VERSION "2024.1"

NS_ :

BS_ :

BU_: SB_FRONT STEERING TPMS DATALOGGER BMS_LV DIAG_TOOL SB_REAR SCANNER EXTRA_NODE TLB_BAT BRUSA DASH DSPACE IMU

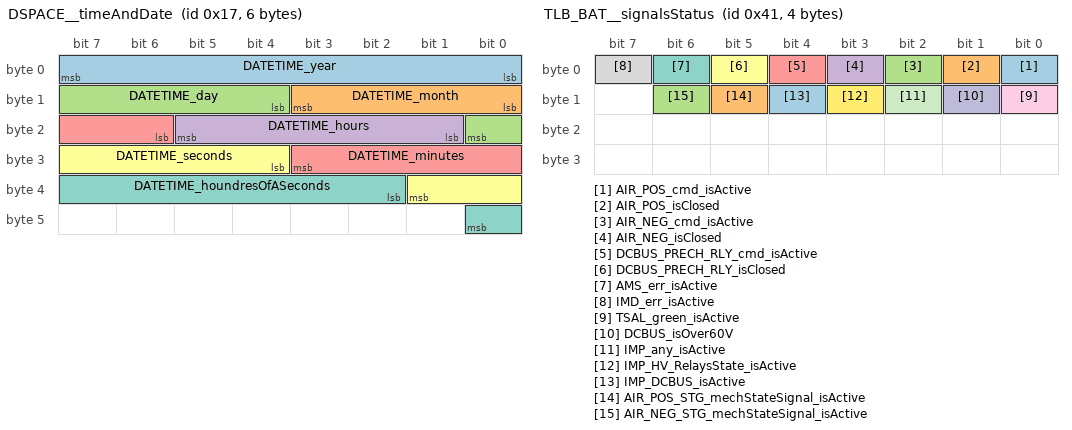
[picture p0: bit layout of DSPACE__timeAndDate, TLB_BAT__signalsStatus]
BO_ 23 DSPACE__timeAndDate: 6 DSPACE
  SG_ DATETIME_year : 0|8@1+ (1,0) [0|255] "" DASH,SB_FRONT,SB_REAR,SCANNER,TLB_BAT,BMS_LV
  SG_ DATETIME_month : 8|4@1+ (1,0) [0|11] "" DASH,SB_FRONT,SB_REAR,SCANNER,TLB_BAT,BMS_LV
  SG_ DATETIME_day : 12|5@1+ (1,0) [1|31] "" DASH,SB_FRONT,SB_REAR,SCANNER,TLB_BAT,BMS_LV
  SG_ DATETIME_hours : 17|5@1+ (1,0) [0|23] "h" DASH,SB_FRONT,SB_REAR,SCANNER,TLB_BAT,BMS_LV
  SG_ DATETIME_minutes : 22|6@1+ (1,0) [0|59] "min" DASH,SB_FRONT,SB_REAR,SCANNER,TLB_BAT,BMS_LV
  SG_ DATETIME_seconds : 28|6@1+ (1,0) [0|59] "sec" DASH,SB_FRONT,SB_REAR,SCANNER,TLB_BAT,BMS_LV
  SG_ DATETIME_houndresOfASeconds : 34|7@1+ (1,0) [0|99] "sec" DASH,SB_FRONT,SB_REAR,SCANNER,TLB_BAT,BMS_LV

BO_ 65 TLB_BAT__signalsStatus: 4 TLB_BAT
  SG_ AIR_POS_cmd_isActive : 0|1@1+ (1,0) [0|1] "" DSPACE,SCANNER
  SG_ AIR_POS_isClosed : 1|1@1+ (1,0) [0|1] "" DSPACE,SCANNER
  SG_ AIR_NEG_cmd_isActive : 2|1@1+ (1,0) [0|1] "" DSPACE,SCANNER
  SG_ AIR_NEG_isClosed : 3|1@1+ (1,0) [0|1] "" DSPACE,SCANNER
  SG_ DCBUS_PRECH_RLY_cmd_isActive : 4|1@1+ (1,0) [0|1] "" DSPACE,SCANNER
  SG_ DCBUS_PRECH_RLY_isClosed : 5|1@1+ (1,0) [0|1] "" DSPACE,SCANNER
  SG_ AMS_err_isActive : 6|1@1+ (1,0) [0|1] "" DSPACE,SCANNER
  SG_ IMD_err_isActive : 7|1@1+ (1,0) [0|1] "" DSPACE,SCANNER
  SG_ TSAL_green_isActive : 8|1@1+ (1,0) [0|1] "" DSPACE,SCANNER
  SG_ DCBUS_isOver60V : 9|1@1+ (1,0) [0|1] "" DSPACE,SCANNER
  SG_ IMP_any_isActive : 10|1@1+ (1,0) [0|1] "" DSPACE,SCANNER
  SG_ IMP_HV_RelaysState_isActive : 11|1@1+ (1,0) [0|1] "" DSPACE,SCANNER
  SG_ IMP_DCBUS_isActive : 12|1@1+ (1,0) [0|1] "" DSPACE,SCANNER
  SG_ AIR_POS_STG_mechStateSignal_isActive : 13|1@1+ (1,0) [0|1] "" DSPACE,SCANNER
  SG_ AIR_NEG_STG_mechStateSignal_isActive : 14|1@1+ (1,0) [0|1] "" DSPACE,SCANNER

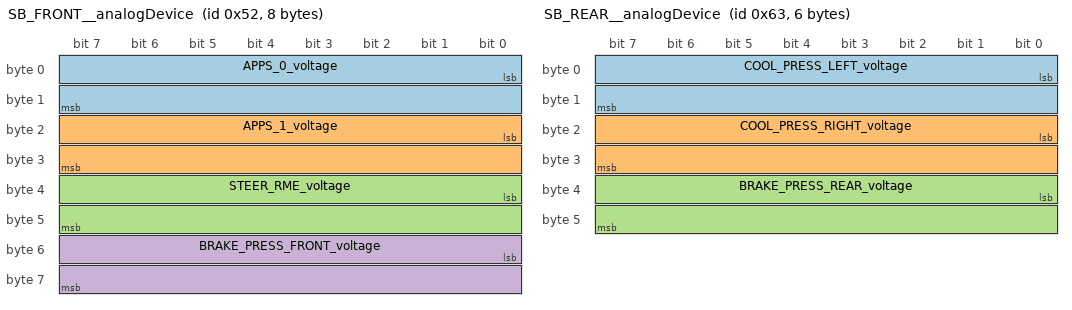
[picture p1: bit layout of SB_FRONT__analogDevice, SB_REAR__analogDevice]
BO_ 82 SB_FRONT__analogDevice: 8 SB_FRONT
  SG_ APPS_0_voltage : 0|16@1+ (1,0) [0|65535] "mV" DSPACE,SCANNER
  SG_ APPS_1_voltage : 16|16@1+ (1,0) [0|65535] "mV" DSPACE,SCANNER
  SG_ STEER_RME_voltage : 32|16@1+ (1,0) [0|65535] "mV" DSPACE,SCANNER
  SG_ BRAKE_PRESS_FRONT_voltage : 48|16@1+ (1,0) [0|8192] "mV" DSPACE,SCANNER

BO_ 83 SB_FRONT_emergency_brake_sensors: 4 SB_FRONT
  SG_ EMERGENCY_BRAKE_PRESS_PNEU_voltage : 0|16@1+ (1,0) [0|65535] "mV" DSPACE,SCANNER
  SG_ REDUNDANCY_BRAKE_PRESS_PNEU_voltage : 16|16@1+ (1,0) [0|65535] "mV" DSPACE,SCANNER

BO_ 99 SB_REAR__analogDevice: 6 SB_REAR
  SG_ COOL_PRESS_LEFT_voltage : 0|16@1+ (1,0) [0|65535] "mV" DSPACE,SCANNER
  SG_ COOL_PRESS_RIGHT_voltage : 16|16@1+ (1,0) [0|65535] "mV" DSPACE,SCANNER
  SG_ BRAKE_PRESS_REAR_voltage : 32|16@1+ (1,0) [0|65535] "mV" DSPACE,SCANNER

BO_ 115 SB_REAR__criticalPeripherals: 1 SB_REAR
  SG_ DISCHARGE_isActive : 0|1@1+ (1,0) [0|1] "" DSPACE,SCANNER
  SG_ BSPD_hasError : 1|1@1+ (1,0) [0|1] "" DSPACE,SCANNER

BO_ 131 SB_REAR__coldplateCircuitPressure: 2 SB_REAR
  SG_ COLDPLATE_CIRCUIT_PRESS_voltage : 0|16@1+ (1,0) [0|65535] "mV" DSPACE,SCANNER

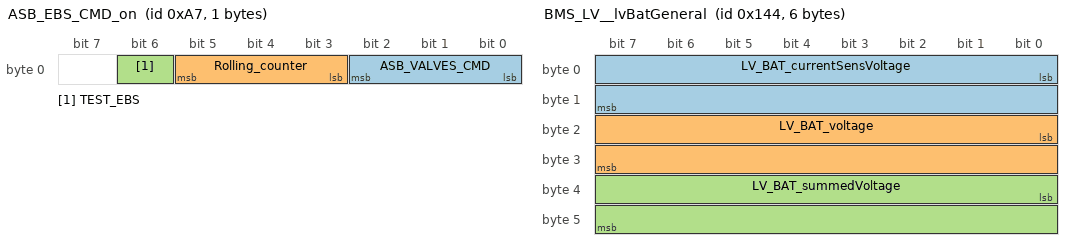
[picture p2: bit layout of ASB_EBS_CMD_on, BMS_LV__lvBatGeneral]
BO_ 167 ASB_EBS_CMD_on: 1 DSPACE
  SG_ ASB_VALVES_CMD : 0|3@1+ (1,0) [1|4] "" DASH
  SG_ Rolling_counter : 3|3@1+ (1,0) [0|7] "" DASH
  SG_ TEST_EBS : 6|1@1+ (1,0) [0|1] "" DASH

BO_ 324 BMS_LV__lvBatGeneral: 6 BMS_LV
  SG_ LV_BAT_currentSensVoltage : 0|16@1+ (0.076,0) [0|4980.66] "mV" DSPACE,SCANNER
  SG_ LV_BAT_voltage : 16|16@1+ (0.267,14000) [0|17497.845] "mV" DSPACE,SCANNER
  SG_ LV_BAT_summedVoltage : 32|16@1+ (0.267,14000) [0|17497.845] "mV" DSPACE,SCANNER

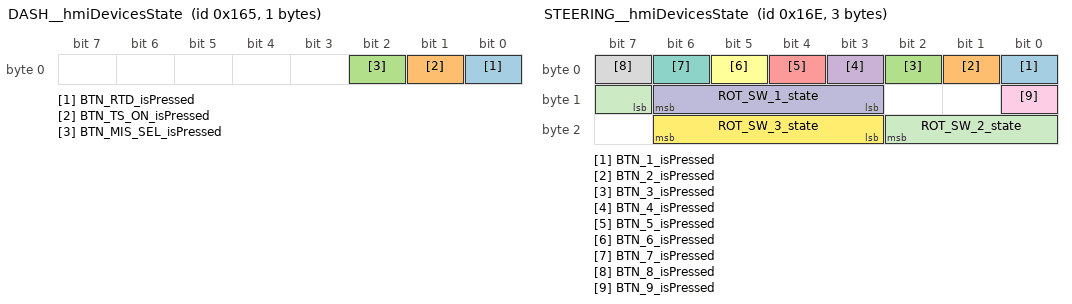
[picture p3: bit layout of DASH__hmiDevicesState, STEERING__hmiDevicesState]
BO_ 357 DASH__hmiDevicesState: 1 DASH
  SG_ BTN_RTD_isPressed : 0|1@1+ (1,0) [0|255] "" DSPACE,SCANNER
  SG_ BTN_TS_ON_isPressed : 1|1@1+ (1,0) [0|255] "" DSPACE,SCANNER
  SG_ BTN_MIS_SEL_isPressed : 2|1@1+ (1,0) [0|255] "" DSPACE,SCANNER

BO_ 366 STEERING__hmiDevicesState: 3 STEERING
  SG_ BTN_1_isPressed : 0|1@1+ (1,0) [0|1] "" DSPACE,SCANNER,DASH
  SG_ BTN_2_isPressed : 1|1@1+ (1,0) [0|1] "" DSPACE,SCANNER,DASH
  SG_ BTN_3_isPressed : 2|1@1+ (1,0) [0|1] "" DSPACE,SCANNER,DASH
  SG_ BTN_4_isPressed : 3|1@1+ (1,0) [0|1] "" DSPACE,SCANNER,DASH
  SG_ BTN_5_isPressed : 4|1@1+ (1,0) [0|1] "" DSPACE,SCANNER,DASH
  SG_ BTN_6_isPressed : 5|1@1+ (1,0) [0|1] "" DSPACE,SCANNER,DASH
  SG_ BTN_7_isPressed : 6|1@1+ (1,0) [0|1] "" DSPACE,SCANNER,DASH
  SG_ BTN_8_isPressed : 7|1@1+ (1,0) [0|1] "" DSPACE,SCANNER,DASH
  SG_ BTN_9_isPressed : 8|1@1+ (1,0) [0|1] "" DSPACE,SCANNER,DASH
  SG_ ROT_SW_1_state : 11|4@1+ (1,0) [0|9] "" DSPACE,SCANNER,DASH
  SG_ ROT_SW_2_state : 15|4@1+ (1,0) [0|9] "" DSPACE,SCANNER,DASH
  SG_ ROT_SW_3_state : 19|4@1+ (1,0) [0|9] "" DSPACE,SCANNER,DASH

BO_ 373 Rolling_not_commuted: 1 DASH
  SG_ No_counter_change_notify : 0|1@1+ (1,0) [0|1] "" DSPACE

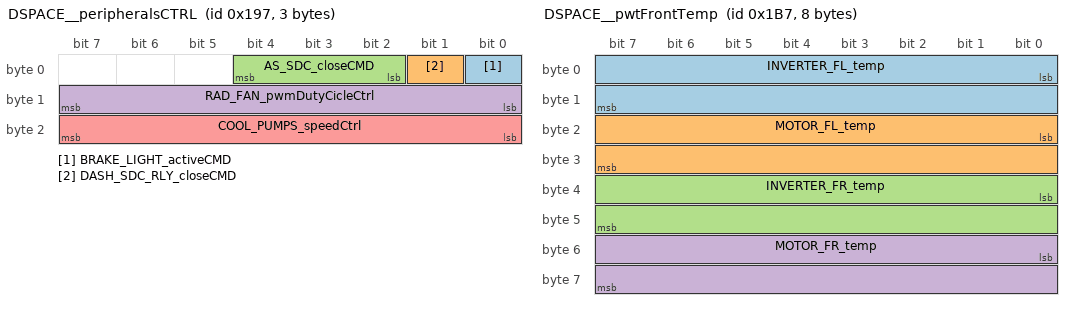
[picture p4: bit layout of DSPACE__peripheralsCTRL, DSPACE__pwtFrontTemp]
BO_ 407 DSPACE__peripheralsCTRL: 3 DSPACE
  SG_ BRAKE_LIGHT_activeCMD : 0|1@1+ (1,0) [0|1] "" DASH,SB_REAR,SCANNER
  SG_ DASH_SDC_RLY_closeCMD : 1|1@1+ (1,0) [0|1] "" DASH,SCANNER
  SG_ AS_SDC_closeCMD : 2|3@1+ (1,0) [0|3] "" DASH,SCANNER
  SG_ RAD_FAN_pwmDutyCicleCtrl : 8|8@1+ (1,0) [0|100] "%" DASH,SB_REAR,SCANNER
  SG_ COOL_PUMPS_speedCtrl : 16|8@1+ (1,0) [0|100] "%" DASH,SB_REAR,SCANNER

BO_ 439 DSPACE__pwtFrontTemp: 8 DSPACE
  SG_ INVERTER_FL_temp : 0|16@1+ (1,0) [-3276|3276] "degC" DASH,SCANNER
  SG_ MOTOR_FL_temp : 16|16@1+ (1,0) [-3276|3276] "degC" DASH,SCANNER
  SG_ INVERTER_FR_temp : 32|16@1+ (1,0) [-3276|3276] "degC" DASH,SCANNER
  SG_ MOTOR_FR_temp : 48|16@1+ (1,0) [-3276|3276] "degC" DASH,SCANNER

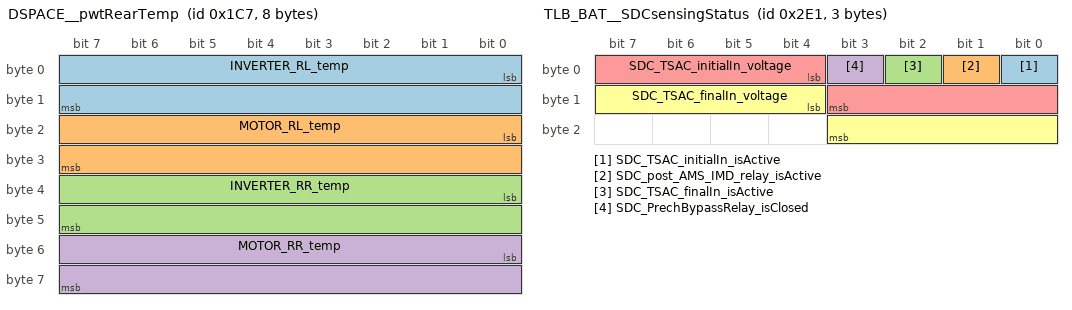
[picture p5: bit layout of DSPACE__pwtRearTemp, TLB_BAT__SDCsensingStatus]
BO_ 455 DSPACE__pwtRearTemp: 8 DSPACE
  SG_ INVERTER_RL_temp : 0|16@1+ (1,0) [-3276|3276] "degC" DASH,SCANNER
  SG_ MOTOR_RL_temp : 16|16@1+ (1,0) [-3276|3276] "degC" DASH,SCANNER
  SG_ INVERTER_RR_temp : 32|16@1+ (1,0) [-3276|3276] "degC" DASH,SCANNER
  SG_ MOTOR_RR_temp : 48|16@1+ (1,0) [-3276|3276] "degC" DASH,SCANNER

BO_ 646 DIAG_TOOL__xcpTxBMS_LV: 8 DIAG_TOOL
  SG_ xcp_payload : 0|64@1+ (1,0) [0|0] "" BMS_LV

BO_ 662 DIAG_TOOL__xcpTxDASH: 8 DIAG_TOOL
  SG_ xcp_payload : 0|64@1+ (1,0) [0|0] "" DASH

BO_ 678 DIAG_TOOL__xcpTxSB_REAR: 8 DIAG_TOOL
  SG_ xcp_payload : 0|64@1+ (1,0) [0|0] "" SB_REAR

BO_ 694 DIAG_TOOL__xcpTxSB_FRONT: 8 DIAG_TOOL
  SG_ xcp_payload : 0|64@1+ (1,0) [0|0] "" SB_FRONT

BO_ 710 DIAG_TOOL__xcpTxSCANNER: 8 DIAG_TOOL
  SG_ xcp_payload : 0|64@1+ (1,0) [0|0] "" SCANNER

BO_ 726 DIAG_TOOL__xcpTxTLB_BAT: 8 DIAG_TOOL
  SG_ xcp_payload : 0|64@1+ (1,0) [0|0] "" TLB_BAT

BO_ 737 TLB_BAT__SDCsensingStatus: 3 TLB_BAT
  SG_ SDC_TSAC_initialIn_isActive : 0|1@1+ (1,0) [0|1] "" DSPACE,SCANNER
  SG_ SDC_post_AMS_IMD_relay_isActive : 1|1@1+ (1,0) [0|1] "" DSPACE,SCANNER
  SG_ SDC_TSAC_finalIn_isActive : 2|1@1+ (1,0) [0|1] "" DSPACE,SCANNER
  SG_ SDC_PrechBypassRelay_isClosed : 3|1@1+ (1,0) [0|1] "" DSPACE,SCANNER
  SG_ SDC_TSAC_initialIn_voltage : 4|8@1+ (0.177,0) [0|255] "V" DSPACE,SCANNER
  SG_ SDC_TSAC_finalIn_voltage : 12|8@1+ (0.177,0) [0|255] "V" DSPACE,SCANNER

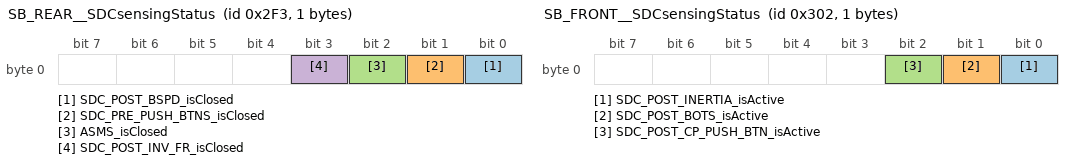
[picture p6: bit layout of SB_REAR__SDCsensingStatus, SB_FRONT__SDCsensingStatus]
BO_ 755 SB_REAR__SDCsensingStatus: 1 SB_REAR
  SG_ SDC_POST_BSPD_isClosed : 0|1@1+ (1,0) [0|1] "" DSPACE,SCANNER
  SG_ SDC_PRE_PUSH_BTNS_isClosed : 1|1@1+ (1,0) [0|1] "" DSPACE,SCANNER
  SG_ ASMS_isClosed : 2|1@1+ (1,0) [0|1] "" DSPACE,SCANNER
  SG_ SDC_POST_INV_FR_isClosed : 3|1@1+ (1,0) [0|1] "" DSPACE,SCANNER

BO_ 770 SB_FRONT__SDCsensingStatus: 1 SB_FRONT
  SG_ SDC_POST_INERTIA_isActive : 0|1@1+ (1,0) [0|1] "" DSPACE,SCANNER
  SG_ SDC_POST_BOTS_isActive : 1|1@1+ (1,0) [0|1] "" DSPACE,SCANNER
  SG_ SDC_POST_CP_PUSH_BTN_isActive : 2|1@1+ (1,0) [0|1] "" DSPACE,SCANNER

BO_ 802 SB_FRONT__potentiometer: 4 SB_FRONT
  SG_ LPPS_DAMPER_FL_voltage : 0|16@1+ (1,0) [0|65535] "mV" DSPACE,SCANNER
  SG_ LPPS_DAMPER_FR_voltage : 16|16@1+ (1,0) [0|65535] "mV" DSPACE,SCANNER

BO_ 819 SB_REAR__potentiometer: 4 SB_REAR
  SG_ LPPS_DAMPER_RL_voltage : 0|16@1+ (1,0) [0|65535] "mV" DSPACE,SCANNER
  SG_ LPPS_DAMPER_RR_voltage : 16|16@1+ (1,0) [0|65535] "mV" DSPACE,SCANNER

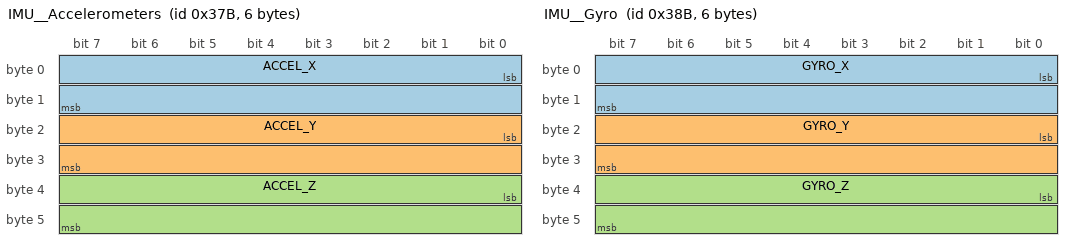
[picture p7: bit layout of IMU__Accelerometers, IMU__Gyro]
BO_ 891 IMU__Accelerometers: 6 IMU
  SG_ ACCEL_X : 0|16@1- (0.01,0) [-327.68|327.67] "m.s-2" Vector__XXX
  SG_ ACCEL_Y : 16|16@1- (0.01,0) [-327.68|327.67] "m.s-2" Vector__XXX
  SG_ ACCEL_Z : 32|16@1- (0.01,0) [-327.68|327.67] "m.s-2" Vector__XXX

BO_ 907 IMU__Gyro: 6 IMU
  SG_ GYRO_X : 0|16@1- (0.001,0) [-32.768|32.767] "rad.s-1" Vector__XXX
  SG_ GYRO_Y : 16|16@1- (0.001,0) [-32.768|32.767] "rad.s-1" Vector__XXX
  SG_ GYRO_Z : 32|16@1- (0.001,0) [-32.768|32.767] "rad.s-1" Vector__XXX

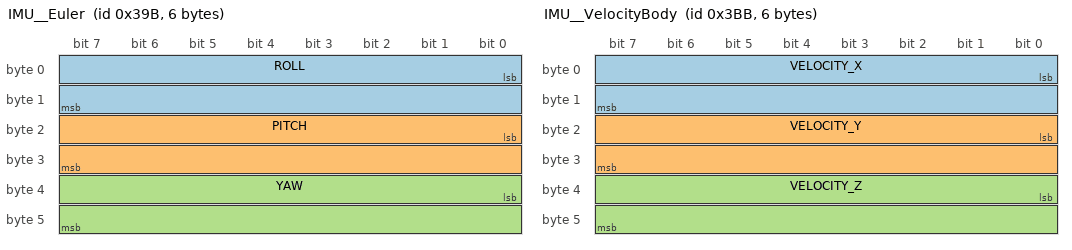
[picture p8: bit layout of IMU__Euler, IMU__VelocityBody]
BO_ 923 IMU__Euler: 6 IMU
  SG_ ROLL : 0|16@1- (0.0001,0) [-3.2768|3.2767] "rad" Vector__XXX
  SG_ PITCH : 16|16@1- (0.0001,0) [-3.2768|3.2767] "rad" Vector__XXX
  SG_ YAW : 32|16@1- (0.0001,0) [-3.2768|3.2767] "rad" Vector__XXX

BO_ 939 IMU__GPS1_Position: 8 IMU
  SG_ LATITUDE : 0|32@1- (0.0000001,0) [-214.7483648|214.7483647] "�" Vector__XXX
  SG_ LONGITUDE : 32|32@1- (0.0000001,0) [-214.7483648|214.7483647] "�" Vector__XXX

BO_ 955 IMU__VelocityBody: 6 IMU
  SG_ VELOCITY_X : 0|16@1- (0.01,0) [-327.68|327.67] "m.s-1" Vector__XXX
  SG_ VELOCITY_Y : 16|16@1- (0.01,0) [-327.68|327.67] "m.s-1" Vector__XXX
  SG_ VELOCITY_Z : 32|16@1- (0.01,0) [-327.68|327.67] "m.s-1" Vector__XXX

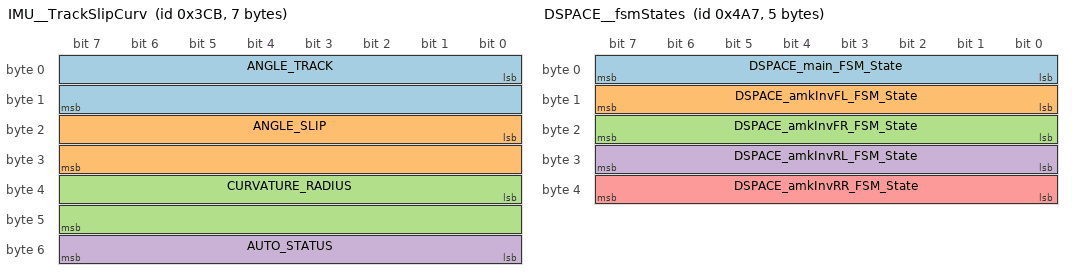
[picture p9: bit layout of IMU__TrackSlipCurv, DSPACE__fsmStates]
BO_ 971 IMU__TrackSlipCurv: 7 IMU
  SG_ ANGLE_TRACK : 0|16@1- (0.0001,0) [-3.2768|3.2767] "rad" Vector__XXX
  SG_ ANGLE_SLIP : 16|16@1- (0.0001,0) [-3.2768|3.2767] "rad" Vector__XXX
  SG_ CURVATURE_RADIUS : 32|16@1+ (0.01,0) [0|655.35] "m" Vector__XXX
  SG_ AUTO_STATUS : 48|8@1+ (1,0) [0|255] "" Vector__XXX

BO_ 1121 TLB_BAT__xcpTx: 8 TLB_BAT
  SG_ xcp_payload : 0|64@1+ (1,0) [0|0] "" DIAG_TOOL

BO_ 1122 SB_FRONT__xcpTx: 8 SB_FRONT
  SG_ xcp_payload : 0|64@1+ (1,0) [0|0] "" DIAG_TOOL

BO_ 1123 SB_REAR__xcpTx: 8 SB_REAR
  SG_ xcp_payload : 0|64@1+ (1,0) [0|0] "" DIAG_TOOL

BO_ 1124 BMS_LV__xcpTx: 8 BMS_LV
  SG_ xcp_payload : 0|64@1+ (1,0) [0|0] "" DIAG_TOOL

BO_ 1125 DASH__xcpTx: 8 DASH
  SG_ xcp_payload : 0|64@1+ (1,0) [0|0] "" DIAG_TOOL

BO_ 1127 DSPACE__xcpTx: 8 DSPACE
  SG_ xcp_payload : 0|64@1+ (1,0) [0|0] "" DIAG_TOOL

BO_ 1129 SCANNER__xcpTx: 8 SCANNER
  SG_ xcp_payload : 0|64@1+ (1,0) [0|0] "" DIAG_TOOL

BO_ 1143 DSPACE__autonomousMission: 1 DSPACE
  SG_ autonomousMission_state : 0|4@1+ (1,0) [0|7] "" DASH,SCANNER

BO_ 1175 DSPACE__signals: 2 DSPACE
  SG_ HVBAT_soc : 0|8@1+ (1,0) [100|0] "%" DASH,SCANNER
  SG_ ASSI_command : 8|3@1+ (1,0) [0|5] "" DASH,SCANNER

BO_ 1191 DSPACE__fsmStates: 5 DSPACE
  SG_ DSPACE_main_FSM_State : 0|8@1- (1,0) [-1|5] "" DASH,SCANNER
  SG_ DSPACE_amkInvFL_FSM_State : 8|8@1- (1,0) [0|6] "" DASH,SCANNER
  SG_ DSPACE_amkInvFR_FSM_State : 16|8@1- (1,0) [0|6] "" DASH,SCANNER
  SG_ DSPACE_amkInvRL_FSM_State : 24|8@1- (1,0) [0|6] "" DASH,SCANNER
  SG_ DSPACE_amkInvRR_FSM_State : 32|8@1- (1,0) [0|6] "" DASH,SCANNER

BO_ 1204 BMS_LV__cellsStatus: 5 BMS_LV
  SG_ LV_CELL_0_isOV : 0|1@1+ (1,0) [0|1] "" DSPACE,SCANNER
  SG_ LV_CELL_0_isUV : 1|1@1+ (1,0) [0|1] "" DSPACE,SCANNER
  SG_ LV_CELL_1_isOV : 2|1@1+ (1,0) [0|1] "" DSPACE,SCANNER
  SG_ LV_CELL_1_isUV : 3|1@1+ (1,0) [0|1] "" DSPACE,SCANNER
  SG_ LV_CELL_2_isOV : 4|1@1+ (1,0) [0|1] "" DSPACE,SCANNER
  SG_ LV_CELL_2_isUV : 5|1@1+ (1,0) [0|1] "" DSPACE,SCANNER
  SG_ LV_CELL_3_isOV : 6|1@1+ (1,0) [0|1] "" DSPACE,SCANNER
  SG_ LV_CELL_3_isUV : 7|1@1+ (1,0) [0|1] "" DSPACE,SCANNER
  SG_ LV_CELL_4_isOV : 8|1@1+ (1,0) [0|1] "" DSPACE,SCANNER
  SG_ LV_CELL_4_isUV : 9|1@1+ (1,0) [0|1] "" DSPACE,SCANNER
  SG_ LV_CELL_5_isOV : 10|1@1+ (1,0) [0|1] "" DSPACE,SCANNER
  SG_ LV_CELL_5_isUV : 11|1@1+ (1,0) [0|1] "" DSPACE,SCANNER
  SG_ LV_CELL_6_isOV : 12|1@1+ (1,0) [0|1] "" DSPACE,SCANNER
  SG_ LV_CELL_6_isUV : 13|1@1+ (1,0) [0|1] "" DSPACE,SCANNER
  SG_ LV_CELL_NTC_00_isOT : 14|1@1+ (1,0) [0|1] "" DSPACE,SCANNER
  SG_ LV_CELL_NTC_01_isOT : 15|1@1+ (1,0) [0|1] "" DSPACE,SCANNER
  SG_ LV_CELL_NTC_02_isOT : 16|1@1+ (1,0) [0|1] "" DSPACE,SCANNER
  SG_ LV_CELL_NTC_03_isOT : 17|1@1+ (1,0) [0|1] "" DSPACE,SCANNER
  SG_ LV_CELL_NTC_04_isOT : 18|1@1+ (1,0) [0|1] "" DSPACE,SCANNER
  SG_ LV_CELL_NTC_05_isOT : 19|1@1+ (1,0) [0|1] "" DSPACE,SCANNER
  SG_ LV_CELL_NTC_06_isOT : 20|1@1+ (1,0) [0|1] "" DSPACE,SCANNER
  SG_ LV_CELL_NTC_07_isOT : 21|1@1+ (1,0) [0|1] "" DSPACE,SCANNER
  SG_ LV_CELL_NTC_08_isOT : 22|1@1+ (1,0) [0|1] "" DSPACE,SCANNER
  SG_ LV_CELL_NTC_09_isOT : 23|1@1+ (1,0) [0|1] "" DSPACE,SCANNER
  SG_ LV_CELL_NTC_10_isOT : 24|1@1+ (1,0) [0|1] "" DSPACE,SCANNER
  SG_ LV_CELL_NTC_11_isOT : 25|1@1+ (1,0) [0|1] "" DSPACE,SCANNER
  SG_ LV_CELL_NTC_12_isOT : 26|1@1+ (1,0) [0|1] "" DSPACE,SCANNER

BO_ 1220 BMS_LV__status: 1 BMS_LV
  SG_ LV_RELAY_isClosed : 0|1@1+ (1,0) [0|1] "" DSPACE,SCANNER
  SG_ LV_RELAY_isRelayOverrideOn : 1|1@1+ (1,0) [0|1] "" DSPACE,SCANNER

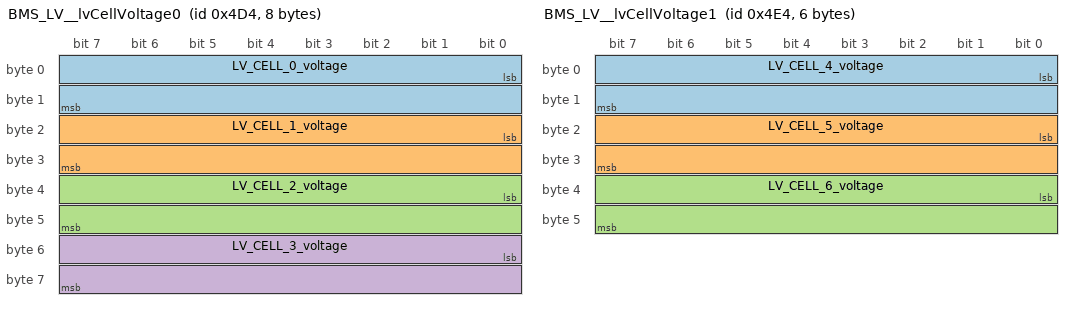
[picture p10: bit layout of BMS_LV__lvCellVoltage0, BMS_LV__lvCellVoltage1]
BO_ 1236 BMS_LV__lvCellVoltage0: 8 BMS_LV
  SG_ LV_CELL_0_voltage : 0|16@1+ (0.038,2000) [0|2490.33] "mV" DSPACE,SCANNER
  SG_ LV_CELL_1_voltage : 16|16@1+ (0.038,2000) [0|2490.33] "mV" DSPACE,SCANNER
  SG_ LV_CELL_2_voltage : 32|16@1+ (0.038,2000) [0|2490.33] "mV" DSPACE,SCANNER
  SG_ LV_CELL_3_voltage : 48|16@1+ (0.038,2000) [0|2490.33] "mV" DSPACE,SCANNER

BO_ 1252 BMS_LV__lvCellVoltage1: 6 BMS_LV
  SG_ LV_CELL_4_voltage : 0|16@1+ (0.038,2000) [0|2490.33] "mV" DSPACE,SCANNER
  SG_ LV_CELL_5_voltage : 16|16@1+ (0.038,2000) [0|2490.33] "mV" DSPACE,SCANNER
  SG_ LV_CELL_6_voltage : 32|16@1+ (0.038,2000) [0|2490.33] "mV" DSPACE,SCANNER

BO_ 1269 DASH__peripheralsStatus: 1 DASH
  SG_ TSAC_FAN_pwmDutyCycleStatus : 0|4@1+ (1,0) [0|10] "%" DSPACE,SCANNER

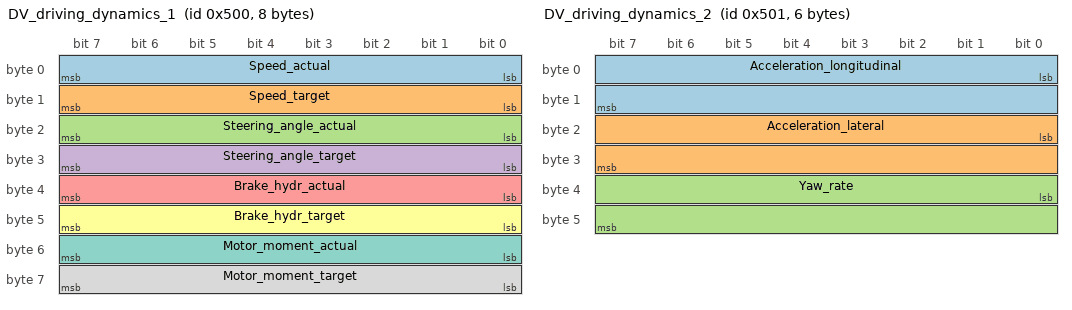
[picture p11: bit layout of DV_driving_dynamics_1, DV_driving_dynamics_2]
BO_ 1280 DV_driving_dynamics_1: 8 DSPACE
  SG_ Speed_actual : 0|8@1+ (1,0) [0|255] "" DATALOGGER
  SG_ Speed_target : 8|8@1+ (1,0) [0|255] "" DATALOGGER
  SG_ Steering_angle_actual : 16|8@1- (0.5,0) [-64|63.5] "" DATALOGGER
  SG_ Steering_angle_target : 24|8@1- (0.5,0) [-64|63.5] "" DATALOGGER
  SG_ Brake_hydr_actual : 32|8@1+ (1,0) [0|255] "" DATALOGGER
  SG_ Brake_hydr_target : 40|8@1+ (1,0) [0|255] "" DATALOGGER
  SG_ Motor_moment_actual : 48|8@1- (1,0) [-128|127] "" DATALOGGER
  SG_ Motor_moment_target : 56|8@1- (1,0) [-128|127] "" DATALOGGER

BO_ 1281 DV_driving_dynamics_2: 6 DSPACE
  SG_ Acceleration_longitudinal : 0|16@1- (0.001953125,0) [-64|63.998046875] "" DATALOGGER
  SG_ Acceleration_lateral : 16|16@1- (0.001953125,0) [-64|63.998046875] "" DATALOGGER
  SG_ Yaw_rate : 32|16@1- (0.0078125,0) [-256|255.9921875] "" DATALOGGER

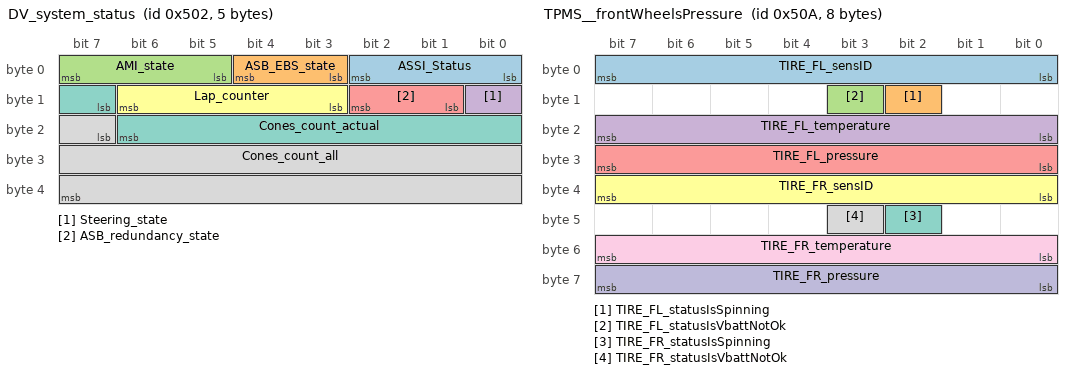
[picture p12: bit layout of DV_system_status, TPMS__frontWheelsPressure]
BO_ 1282 DV_system_status: 5 DSPACE
  SG_ ASSI_Status : 0|3@1+ (1,0) [1|5] "" DATALOGGER,DASH
  SG_ ASB_EBS_state : 3|2@1+ (1,0) [1|3] "" DATALOGGER,DASH
  SG_ AMI_state : 5|3@1+ (1,0) [1|6] "" DATALOGGER,DASH
  SG_ Steering_state : 8|1@1+ (1,0) [0|1] "" DATALOGGER
  SG_ ASB_redundancy_state : 9|2@1+ (1,0) [1|3] "" DATALOGGER
  SG_ Lap_counter : 11|4@1+ (1,0) [0|15] "" DATALOGGER
  SG_ Cones_count_actual : 15|8@1+ (1,0) [0|255] "" DATALOGGER
  SG_ Cones_count_all : 23|17@1+ (1,0) [0|131071] "" DATALOGGER

BO_ 1290 TPMS__frontWheelsPressure: 8 TPMS
  SG_ TIRE_FL_sensID : 0|8@1+ (1,0) [1|255] "" DSPACE,SCANNER
  SG_ TIRE_FL_statusIsSpinning : 10|1@1+ (1,0) [0|1] "" DSPACE,SCANNER
  SG_ TIRE_FL_statusIsVbattNotOk : 11|1@1+ (1,0) [0|1] "" DSPACE,SCANNER
  SG_ TIRE_FL_temperature : 16|8@1+ (1,-50) [10|170] "degC" DSPACE,SCANNER
  SG_ TIRE_FL_pressure : 24|8@1+ (13.7035,-0.7035) [1|254] "mB" DSPACE,SCANNER
  SG_ TIRE_FR_sensID : 32|8@1+ (1,0) [1|255] "" DSPACE,SCANNER
  SG_ TIRE_FR_statusIsSpinning : 42|1@1+ (1,0) [0|1] "" DSPACE,SCANNER
  SG_ TIRE_FR_statusIsVbattNotOk : 43|1@1+ (1,0) [0|1] "" DSPACE,SCANNER
  SG_ TIRE_FR_temperature : 48|8@1+ (1,-50) [10|170] "degC" DSPACE,SCANNER
  SG_ TIRE_FR_pressure : 56|8@1+ (13.7035,-0.7035) [1|254] "mB" DSPACE,SCANNER

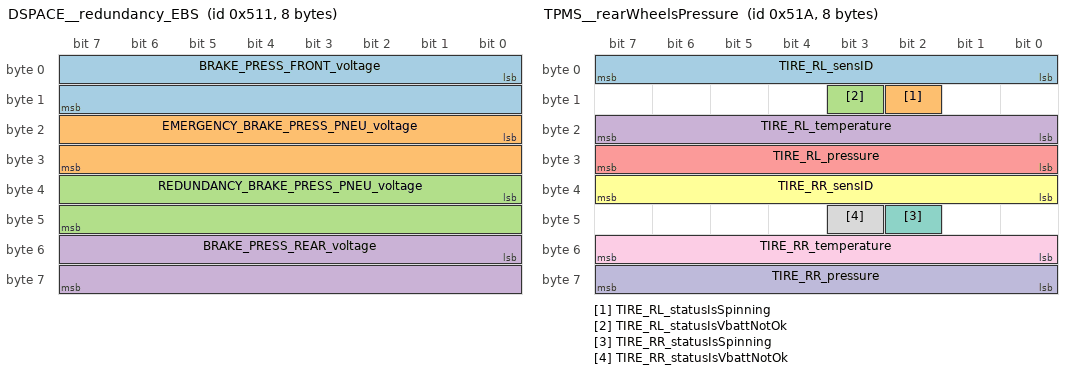
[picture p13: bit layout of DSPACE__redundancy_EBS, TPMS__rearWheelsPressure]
BO_ 1297 DSPACE__redundancy_EBS: 8 DSPACE
  SG_ BRAKE_PRESS_FRONT_voltage : 0|16@1+ (0.025,-12.5) [0|200] "bar" SB_FRONT,DATALOGGER
  SG_ EMERGENCY_BRAKE_PRESS_PNEU_voltage : 16|16@1+ (0.025,-12.5) [0|200] "bar" SB_FRONT,DATALOGGER
  SG_ REDUNDANCY_BRAKE_PRESS_PNEU_voltage : 32|16@1+ (0.025,-12.5) [0|200] "bar" SB_FRONT,DATALOGGER
  SG_ BRAKE_PRESS_REAR_voltage : 48|16@1+ (0.025,-12.5) [0|200] "bar" SB_REAR,DATALOGGER

BO_ 1306 TPMS__rearWheelsPressure: 8 TPMS
  SG_ TIRE_RL_sensID : 0|8@1+ (1,0) [1|255] "" DSPACE,SCANNER
  SG_ TIRE_RL_statusIsSpinning : 10|1@1+ (1,0) [0|1] "" DSPACE,SCANNER
  SG_ TIRE_RL_statusIsVbattNotOk : 11|1@1+ (1,0) [0|1] "" DSPACE,SCANNER
  SG_ TIRE_RL_temperature : 16|8@1+ (1,-50) [10|170] "degC" DSPACE,SCANNER
  SG_ TIRE_RL_pressure : 24|8@1+ (13.7035,-0.7035) [1|254] "mB" DSPACE,SCANNER
  SG_ TIRE_RR_sensID : 32|8@1+ (1,0) [1|255] "" DSPACE,SCANNER
  SG_ TIRE_RR_statusIsSpinning : 42|1@1+ (1,0) [0|1] "" DSPACE,SCANNER
  SG_ TIRE_RR_statusIsVbattNotOk : 43|1@1+ (1,0) [0|1] "" DSPACE,SCANNER
  SG_ TIRE_RR_temperature : 48|8@1+ (1,-50) [10|170] "degC" DSPACE,SCANNER
  SG_ TIRE_RR_pressure : 56|8@1+ (13.7035,-0.7035) [1|254] "mB" DSPACE,SCANNER

BO_ 1552 NLG5_ST: 4 BRUSA
  SG_ NLG5_S_CP_DT : 0|1@0+ (1,0) [0|1] "" SCANNER
  SG_ NLG5_S_UM_II : 1|1@0+ (1,0) [0|1] "" SCANNER
  SG_ NLG5_S_UM_I : 2|1@0+ (1,0) [0|1] "" SCANNER
  SG_ NLG5_S_EUM : 3|1@0+ (1,0) [0|1] "" SCANNER
  SG_ NLG5_S_FAN : 4|1@0+ (1,0) [0|1] "" SCANNER
  SG_ NLG5_S_WAR : 5|1@0+ (1,0) [0|1] "" SCANNER
  SG_ NLG5_S_ERR : 6|1@0+ (1,0) [0|1] "" SCANNER
  SG_ NLG5_S_HE : 7|1@0+ (1,0) [0|1] "" SCANNER
  SG_ NLG5_S_L_PMAX : 8|1@0+ (1,0) [0|1] "" SCANNER
  SG_ NLG5_S_L_CP : 9|1@0+ (1,0) [0|1] "" SCANNER
  SG_ NLG5_S_L_PI : 10|1@0+ (1,0) [0|1] "" SCANNER
  SG_ NLG5_S_L_MC : 11|1@0+ (1,0) [0|1] "" SCANNER
  SG_ NLG5_S_L_OC : 12|1@0+ (1,0) [0|1] "" SCANNER
  SG_ NLG5_S_L_OV : 13|1@0+ (1,0) [0|1] "" SCANNER
  SG_ NLG5_S_BPD_II : 14|1@0+ (1,0) [0|1] "" SCANNER
  SG_ NLG5_S_BPD_I : 15|1@0+ (1,0) [0|1] "" SCANNER
  SG_ NLG5_S_L_T_BATT : 16|1@0+ (1,0) [0|1] "" SCANNER
  SG_ NLG5_S_L_T_TR : 17|1@0+ (1,0) [0|1] "" SCANNER
  SG_ NLG5_S_L_T_DIO : 18|1@0+ (1,0) [0|1] "" SCANNER
  SG_ NLG5_S_L_T_POW : 19|1@0+ (1,0) [0|1] "" SCANNER
  SG_ NLG5_S_L_T_CPRIM : 20|1@0+ (1,0) [0|1] "" SCANNER
  SG_ NLG5_S_L_MO_MAX : 21|1@0+ (1,0) [0|1] "" SCANNER
  SG_ NLG5_S_L_OC_MAX : 22|1@0+ (1,0) [0|1] "" SCANNER
  SG_ NLG5_S_L_MC_MAX : 23|1@0+ (1,0) [0|1] "" SCANNER
  SG_ NLG5_S_AAC : 24|1@0+ (1,0) [0|1] "" SCANNER

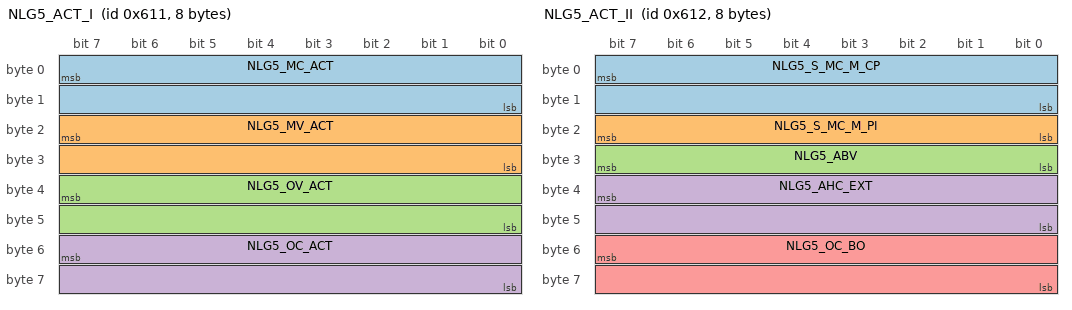
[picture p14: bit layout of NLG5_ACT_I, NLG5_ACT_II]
BO_ 1553 NLG5_ACT_I: 8 BRUSA
  SG_ NLG5_MC_ACT : 7|16@0+ (0.01,0) [0|50] "A" SCANNER
  SG_ NLG5_MV_ACT : 23|16@0+ (0.1,0) [0|500] "V" SCANNER
  SG_ NLG5_OV_ACT : 39|16@0+ (0.1,0) [0|1000] "V" SCANNER
  SG_ NLG5_OC_ACT : 55|16@0- (0.01,0) [0|150] "A" SCANNER

BO_ 1554 NLG5_ACT_II: 8 BRUSA
  SG_ NLG5_S_MC_M_CP : 7|16@0+ (0.1,0) [0|100] "A" SCANNER
  SG_ NLG5_S_MC_M_PI : 23|8@0+ (0.1,0) [0|20] "A" SCANNER
  SG_ NLG5_ABV : 31|8@0+ (0.1,0) [0|25] "V" SCANNER
  SG_ NLG5_AHC_EXT : 39|16@0- (0.01,0) [-327.68|327.67] "Ah" SCANNER
  SG_ NLG5_OC_BO : 55|16@0+ (0.01,0) [0|50] "A" SCANNER

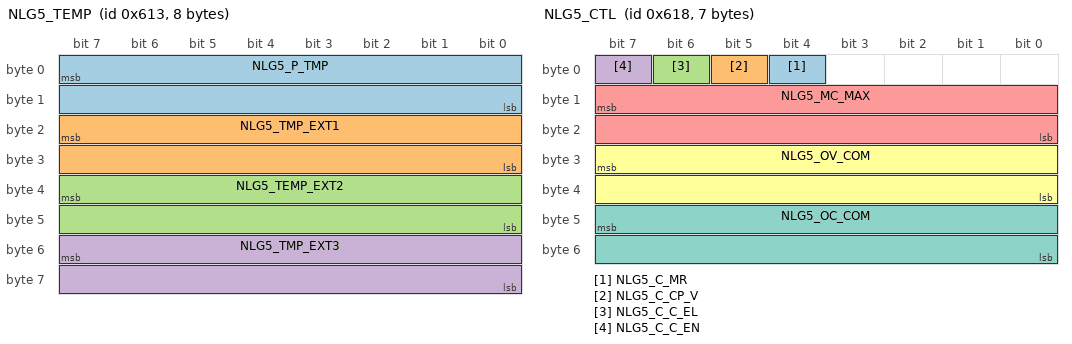
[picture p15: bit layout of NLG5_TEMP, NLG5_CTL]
BO_ 1555 NLG5_TEMP: 8 BRUSA
  SG_ NLG5_P_TMP : 7|16@0- (0.1,0) [-40|300] "degC" SCANNER
  SG_ NLG5_TMP_EXT1 : 23|16@0- (0.1,0) [-40|300] "degC" SCANNER
  SG_ NLG5_TEMP_EXT2 : 39|16@0- (0.1,0) [-40|300] "degC" SCANNER
  SG_ NLG5_TMP_EXT3 : 55|16@0- (0.1,0) [-40|300] "degC" SCANNER

BO_ 1556 NLG5_ERR: 5 BRUSA
  SG_ NLG5_E_MF : 0|1@0+ (1,0) [0|1] "" SCANNER
  SG_ NLG5_E_OF : 1|1@0+ (1,0) [0|1] "" SCANNER
  SG_ NLG5_E_P_MV : 2|1@0+ (1,0) [0|1] "" SCANNER
  SG_ NLG5_E_P_OM : 3|1@0+ (1,0) [0|1] "" SCANNER
  SG_ NLG5_E_SC : 4|1@0+ (1,0) [0|1] "" SCANNER
  SG_ NLG5_E_MOV_I : 5|1@0+ (1,0) [0|1] "" SCANNER
  SG_ NLG5_E_MOV_II : 6|1@0+ (1,0) [0|1] "" SCANNER
  SG_ NLG5_E_OOV : 7|1@0+ (1,0) [0|1] "" SCANNER
  SG_ NLG5_E_T_EXT3 : 8|1@0+ (1,0) [0|1] "" SCANNER
  SG_ NLG5_E_T_EXT2 : 9|1@0+ (1,0) [0|1] "" SCANNER
  SG_ NLG5_E_T_EXT1 : 10|1@0+ (1,0) [0|1] "" SCANNER
  SG_ NLG5_E_T_TR : 11|1@0+ (1,0) [0|1] "" SCANNER
  SG_ NLG5_E_T_DIO : 12|1@0+ (1,0) [0|1] "" SCANNER
  SG_ NLG5_E_T_POW : 13|1@0+ (1,0) [0|1] "" SCANNER
  SG_ NLG5_E_T_C : 14|1@0+ (1,0) [0|1] "" SCANNER
  SG_ NLG5_E_B_P : 15|1@0+ (1,0) [0|1] "" SCANNER
  SG_ NLG5_E_C_OFF : 16|1@0+ (1,0) [0|1] "" SCANNER
  SG_ NLG5_E_C_TO : 17|1@0+ (1,0) [0|1] "" SCANNER
  SG_ NLG5_E_INIT : 18|1@0+ (1,0) [0|1] "" SCANNER
  SG_ NLG5_E_WDT : 19|1@0+ (1,0) [0|1] "" SCANNER
  SG_ NLG5_E_EP_CRC : 20|1@0+ (1,0) [0|1] "" SCANNER
  SG_ NLG5_E_ES_CRC : 21|1@0+ (1,0) [0|1] "" SCANNER
  SG_ NLG5_E_NV_CRC : 22|1@0+ (1,0) [0|1] "" SCANNER
  SG_ NLG5_E_F_CRC : 23|1@0+ (1,0) [0|1] "" SCANNER
  SG_ NLG5_E_SDT_CT : 26|1@0+ (1,0) [0|1] "" SCANNER
  SG_ NLG5_E_SDT_AH : 27|1@0+ (1,0) [0|1] "" SCANNER
  SG_ NLG5_E_SDT_BV : 28|1@0+ (1,0) [0|1] "" SCANNER
  SG_ NLG5_E_SDT_BT : 29|1@0+ (1,0) [0|1] "" SCANNER
  SG_ NLG5_E_C_RX : 30|1@0+ (1,0) [0|1] "" SCANNER
  SG_ NLG5_E_C_TX : 31|1@0+ (1,0) [0|1] "" SCANNER
  SG_ NLG5_W_SC_M : 32|1@0+ (1,0) [0|0] "" SCANNER
  SG_ NLG5_W_OD : 33|1@0+ (1,0) [0|0] "" Vector__XXX
  SG_ NLG5_W_CM_NA : 35|1@0+ (1,0) [0|0] "" Vector__XXX
  SG_ NLG5_W_C_VOR : 36|1@0+ (1,0) [0|1] "" SCANNER
  SG_ NLG5_W_PL_IT : 37|1@0+ (1,0) [0|1] "" SCANNER
  SG_ NLG5_W_PL_BV : 38|1@0+ (1,0) [0|1] "" SCANNER
  SG_ NLG5_W_PL_MV : 39|1@0+ (1,0) [0|1] "" SCANNER

BO_ 1560 NLG5_CTL: 7 BRUSA
  SG_ NLG5_C_MR : 4|1@0+ (1,0) [0|1] "" BRUSA,SCANNER
  SG_ NLG5_C_CP_V : 5|1@0+ (1,0) [0|1] "" BRUSA,SCANNER
  SG_ NLG5_C_C_EL : 6|1@0+ (1,0) [0|1] "" BRUSA,SCANNER
  SG_ NLG5_C_C_EN : 7|1@0+ (1,0) [0|1] "" BRUSA,SCANNER
  SG_ NLG5_MC_MAX : 15|16@0+ (0.1,0) [0|50] "A" BRUSA,SCANNER
  SG_ NLG5_OV_COM : 31|16@0+ (0.1,0) [0|1000] "V" BRUSA,SCANNER
  SG_ NLG5_OC_COM : 47|16@0+ (0.1,0) [0|150] "A" BRUSA,SCANNER

BO_ 1601 TLB_BAT__hello: 3 TLB_BAT
  SG_ FW_majorVersion : 0|8@1+ (1,0) [0|255] "" DSPACE,SCANNER
  SG_ FW_minorVersion : 8|8@1+ (1,0) [0|255] "" DSPACE,SCANNER
  SG_ FW_patchVersion : 16|8@1+ (1,0) [0|255] "" DSPACE,SCANNER

BO_ 1602 SB_FRONT__hello: 3 SB_FRONT
  SG_ FW_majorVersion : 0|8@1+ (1,0) [0|255] "" DSPACE,SCANNER
  SG_ FW_minorVersion : 8|8@1+ (1,0) [0|255] "" DSPACE,SCANNER
  SG_ FW_patchVersion : 16|8@1+ (1,0) [0|255] "" DSPACE,SCANNER

BO_ 1603 SB_REAR__hello: 3 SB_REAR
  SG_ FW_majorVersion : 0|8@1+ (1,0) [0|255] "" DSPACE,SCANNER
  SG_ FW_minorVersion : 8|8@1+ (1,0) [0|255] "" DSPACE,SCANNER
  SG_ FW_patchVersion : 16|8@1+ (1,0) [0|255] "" DSPACE,SCANNER

BO_ 1604 BMS_LV__hello: 3 BMS_LV
  SG_ FW_majorVersion : 0|8@1+ (1,0) [0|255] "" DSPACE,SCANNER
  SG_ FW_minorVersion : 8|8@1+ (1,0) [0|255] "" DSPACE,SCANNER
  SG_ FW_patchVersion : 16|8@1+ (1,0) [0|255] "" DSPACE,SCANNER

BO_ 1605 DASH__hello: 3 DASH
  SG_ FW_majorVersion : 0|8@1+ (1,0) [0|255] "" DSPACE,SCANNER
  SG_ FW_minorVersion : 8|8@1+ (1,0) [0|255] "" DSPACE,SCANNER
  SG_ FW_patchVersion : 16|8@1+ (1,0) [0|255] "" DSPACE,SCANNER

BO_ 1607 DSPACE__hello: 3 DSPACE
  SG_ FW_majorVersion : 0|8@1+ (1,0) [0|255] "" SCANNER
  SG_ FW_minorVersion : 8|8@1+ (1,0) [0|255] "" SCANNER
  SG_ FW_patchVersion : 16|8@1+ (1,0) [0|255] "" SCANNER

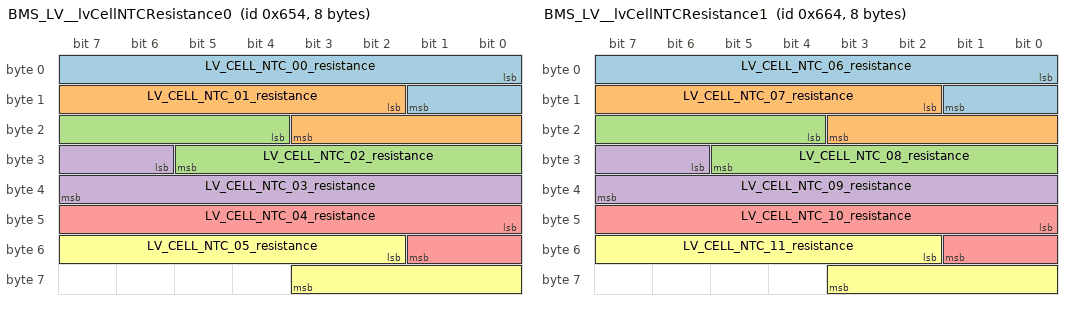
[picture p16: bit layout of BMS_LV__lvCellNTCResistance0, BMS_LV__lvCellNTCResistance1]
BO_ 1620 BMS_LV__lvCellNTCResistance0: 8 BMS_LV
  SG_ LV_CELL_NTC_00_resistance : 0|10@1+ (31.25,1000) [0|31968.75] "Ohm" DSPACE,SCANNER
  SG_ LV_CELL_NTC_01_resistance : 10|10@1+ (31.25,1000) [0|31968.75] "Ohm" DSPACE,SCANNER
  SG_ LV_CELL_NTC_02_resistance : 20|10@1+ (31.25,1000) [0|31968.75] "Ohm" DSPACE,SCANNER
  SG_ LV_CELL_NTC_03_resistance : 30|10@1+ (31.25,1000) [0|31968.75] "Ohm" DSPACE,SCANNER
  SG_ LV_CELL_NTC_04_resistance : 40|10@1+ (31.25,1000) [0|31968.75] "Ohm" DSPACE,SCANNER
  SG_ LV_CELL_NTC_05_resistance : 50|10@1+ (31.25,1000) [0|31968.75] "Ohm" DSPACE,SCANNER

BO_ 1636 BMS_LV__lvCellNTCResistance1: 8 BMS_LV
  SG_ LV_CELL_NTC_06_resistance : 0|10@1+ (31.25,1000) [0|31968.75] "Ohm" DSPACE,SCANNER
  SG_ LV_CELL_NTC_07_resistance : 10|10@1+ (31.25,1000) [0|31968.75] "Ohm" DSPACE,SCANNER
  SG_ LV_CELL_NTC_08_resistance : 20|10@1+ (31.25,1000) [0|31968.75] "Ohm" DSPACE,SCANNER
  SG_ LV_CELL_NTC_09_resistance : 30|10@1+ (31.25,1000) [0|31968.75] "Ohm" DSPACE,SCANNER
  SG_ LV_CELL_NTC_10_resistance : 40|10@1+ (31.25,1000) [0|31968.75] "Ohm" DSPACE,SCANNER
  SG_ LV_CELL_NTC_11_resistance : 50|10@1+ (31.25,1000) [0|31968.75] "Ohm" DSPACE,SCANNER

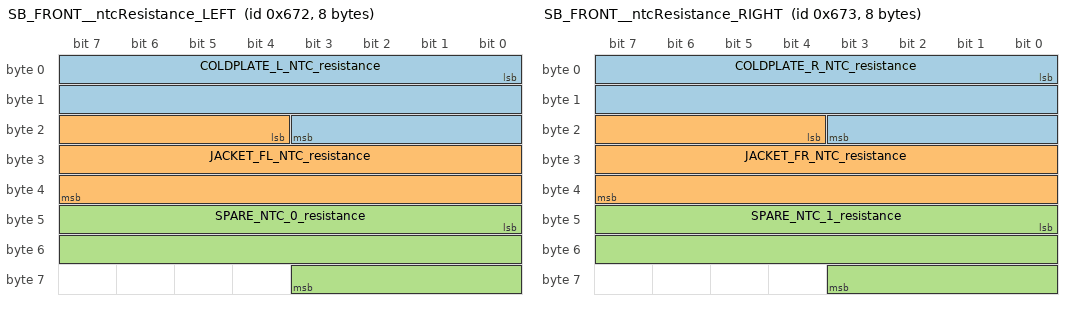
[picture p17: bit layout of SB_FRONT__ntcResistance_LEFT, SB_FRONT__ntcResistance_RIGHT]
BO_ 1650 SB_FRONT__ntcResistance_LEFT: 8 SB_FRONT
  SG_ COLDPLATE_L_NTC_resistance : 0|20@1+ (31.25,1000) [0|31968.75] "Ohm" DSPACE,SCANNER
  SG_ JACKET_FL_NTC_resistance : 20|20@1+ (31.25,1000) [0|31968.75] "Ohm" DSPACE,SCANNER
  SG_ SPARE_NTC_0_resistance : 40|20@1+ (31.25,1000) [0|31968.75] "Ohm" DSPACE,SCANNER

BO_ 1651 SB_FRONT__ntcResistance_RIGHT: 8 SB_FRONT
  SG_ COLDPLATE_R_NTC_resistance : 0|20@1+ (31.25,1000) [0|31968.75] "Ohm" DSPACE,SCANNER
  SG_ JACKET_FR_NTC_resistance : 20|20@1+ (31.25,1000) [0|31968.75] "Ohm" DSPACE,SCANNER
  SG_ SPARE_NTC_1_resistance : 40|20@1+ (31.25,1000) [0|31968.75] "Ohm" DSPACE,SCANNER

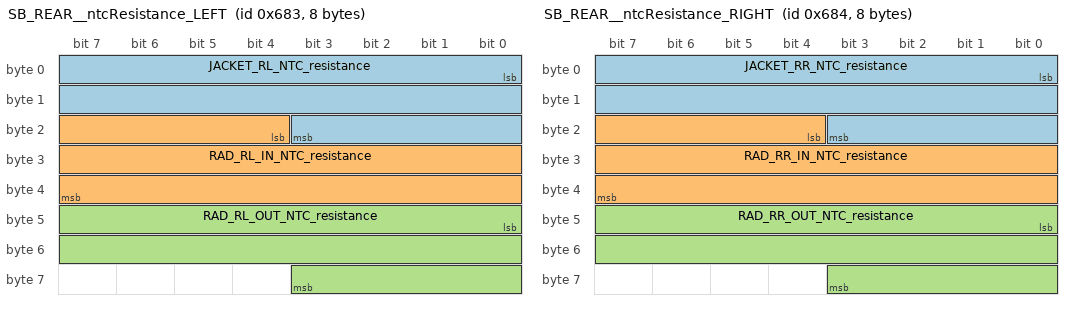
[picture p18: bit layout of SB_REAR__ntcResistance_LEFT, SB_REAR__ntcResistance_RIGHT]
BO_ 1667 SB_REAR__ntcResistance_LEFT: 8 SB_REAR
  SG_ JACKET_RL_NTC_resistance : 0|20@1+ (31.25,0) [0|31968.75] "Ohm" DSPACE,SCANNER
  SG_ RAD_RL_IN_NTC_resistance : 20|20@1+ (31.25,0) [0|31968.75] "Ohm" DSPACE,SCANNER
  SG_ RAD_RL_OUT_NTC_resistance : 40|20@1+ (31.25,0) [0|31968.75] "Ohm" DSPACE,SCANNER

BO_ 1668 SB_REAR__ntcResistance_RIGHT: 8 SB_REAR
  SG_ JACKET_RR_NTC_resistance : 0|20@1+ (31.25,0) [0|31968.75] "Ohm" DSPACE,SCANNER
  SG_ RAD_RR_IN_NTC_resistance : 20|20@1+ (31.25,0) [0|31968.75] "Ohm" DSPACE,SCANNER
  SG_ RAD_RR_OUT_NTC_resistance : 40|20@1+ (31.25,0) [0|31968.75] "Ohm" DSPACE,SCANNER

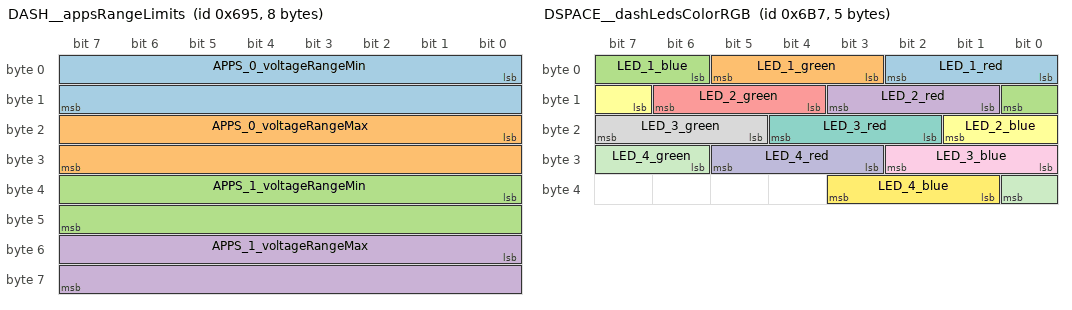
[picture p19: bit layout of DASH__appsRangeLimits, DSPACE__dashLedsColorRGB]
BO_ 1685 DASH__appsRangeLimits: 8 DASH
  SG_ APPS_0_voltageRangeMin : 0|16@1+ (1,0) [0|65535] "mV" DSPACE,SCANNER
  SG_ APPS_0_voltageRangeMax : 16|16@1+ (1,0) [0|65535] "mV" DSPACE,SCANNER
  SG_ APPS_1_voltageRangeMin : 32|16@1+ (1,0) [0|65535] "mV" DSPACE,SCANNER
  SG_ APPS_1_voltageRangeMax : 48|16@1+ (1,0) [0|65535] "mV" DSPACE,SCANNER

BO_ 1701 DASH__carCommands: 3 DASH
  SG_ BMS_LV_diagPWD : 0|16@1+ (1,0) [0|32768] "" BMS_LV
  SG_ LV_RELAY_overrideState : 16|2@1+ (1,0) [0|2] "" BMS_LV

BO_ 1719 DSPACE__dashLedsColorRGB: 5 DSPACE
  SG_ LED_1_red : 0|3@1+ (1,0) [0|7] "" Vector__XXX
  SG_ LED_1_green : 3|3@1+ (1,0) [0|7] "" Vector__XXX
  SG_ LED_1_blue : 6|3@1+ (1,0) [0|7] "" Vector__XXX
  SG_ LED_2_red : 9|3@1+ (1,0) [0|7] "" Vector__XXX
  SG_ LED_2_green : 12|3@1+ (1,0) [0|7] "" Vector__XXX
  SG_ LED_2_blue : 15|3@1+ (1,0) [0|7] "" Vector__XXX
  SG_ LED_3_red : 18|3@1+ (1,0) [0|7] "" Vector__XXX
  SG_ LED_3_green : 21|3@1+ (1,0) [0|7] "" Vector__XXX
  SG_ LED_3_blue : 24|3@1+ (1,0) [0|7] "" Vector__XXX
  SG_ LED_4_red : 27|3@1+ (1,0) [0|7] "" Vector__XXX
  SG_ LED_4_green : 30|3@1+ (1,0) [0|7] "" Vector__XXX
  SG_ LED_4_blue : 33|3@1+ (1,0) [0|7] "" Vector__XXX

BO_ 1748 BMS_LV__lvCellNTCResistance2: 8 BMS_LV
  SG_ LV_CELL_NTC_12_resistance : 0|10@1+ (31.25,1000) [0|31968.75] "Ohm" DSPACE,SCANNER

BO_ 1800 IRTS_placeholderMessage: 8 EXTRA_NODE
  SG_ IRTS_signalPlaceholder : 0|64@1+ (1,0) [0|65535] "" Vector__XXX

BO_ 1816 NLG5_DIAG_RX: 8 BRUSA
  SG_ LAD_D_ParamRq : 7|64@0+ (1,0) [0|0] "" BRUSA,SCANNER

BO_ 1818 NLG5_DIAG_TX: 8 BRUSA
  SG_ LAD_D_ParamRp : 7|64@0+ (1,0) [0|0] "" BRUSA,SCANNER

CM_ BU_ DASH "Dashboard ECU";
CM_ BU_ DSPACE "An automotive ECU";
CM_ BU_ IMU "Inertial Measurement Unit.";
CM_ BU_ SB_FRONT "Sensorboard front ECU";
CM_ BU_ STEERING "Steering wheel board";
CM_ BU_ BMS_LV "Battery-Management-System Low-Voltage ECU";
CM_ BU_ DIAG_TOOL "Diagnostic tool";
CM_ BU_ SB_REAR "Sensorboard rear ECU";
CM_ BU_ SCANNER "Can Logger ECU";
CM_ BU_ TPMS "Tire pressure monitoring system";
CM_ BU_ DATALOGGER "DataLogger provided by race organizers";
CM_ BU_ EXTRA_NODE "Extra CAN BUS-Nodes not permanent or temporary";
CM_ BU_ TLB_BAT "TSAL-latch-board battery ECU";
CM_ BU_ BRUSA "Brusa NLG5 charger.";
CM_ BO_ 439 "(cycle_time: 100) (send_type: Cyclic)";
CM_ SG_ 439 INVERTER_FL_temp "The temperature of the front left inverter";
CM_ SG_ 439 MOTOR_FL_temp "The temperature of the front left motor";
CM_ SG_ 439 INVERTER_FR_temp "The temperature of the front right inverter";
CM_ SG_ 439 MOTOR_FR_temp "The temperature of the front right motor";
CM_ BO_ 455 "(cycle_time: 100) (send_type: Cyclic)";
CM_ SG_ 455 INVERTER_RL_temp "The temperature of the rear left inverter";
CM_ SG_ 455 MOTOR_RL_temp "The temperature of the rear left motor";
CM_ SG_ 455 INVERTER_RR_temp "The temperature of the rear right inverter";
CM_ SG_ 455 MOTOR_RR_temp "The temperature of the rear right motor";
CM_ BO_ 1603 "(send_type: IfActive)";
CM_ SG_ 1603 FW_majorVersion "firmware major version number";
CM_ SG_ 1603 FW_minorVersion "firmware minor version number";
CM_ SG_ 1603 FW_patchVersion "firmware patch version number";
CM_ BO_ 1605 "(send_type: IfActive)";
CM_ SG_ 1605 FW_majorVersion "firmware major version number";
CM_ SG_ 1605 FW_minorVersion "firmware minor version number";
CM_ SG_ 1605 FW_patchVersion "firmware patch version number";
CM_ BO_ 1306 "(send_type: CyclicIfActive)";
CM_ SG_ 1306 TIRE_RL_sensID "The sensor id of the Rear Left tire";
CM_ SG_ 1306 TIRE_RL_statusIsSpinning "Acc bit of Rear Left tire status register: wheel is spinning (1) or not (0)";
CM_ SG_ 1306 TIRE_RL_temperature "The temperature of the Rear Left tire";
CM_ SG_ 1306 TIRE_RR_sensID "The sensor id of the front right tire";
CM_ SG_ 1306 TIRE_RR_statusIsSpinning "Acc bit of Rear Right tire status register: wheel is spinning (1) or not (0)";
CM_ SG_ 1306 TIRE_RR_temperature "The temperature of the Rear Right tire";
CM_ SG_ 1306 TIRE_RL_statusIsVbattNotOk "Vbatt bit of Rear Left tire status register: TPMS battery is below 2.2V (1) or above (0)";
CM_ SG_ 1306 TIRE_RL_pressure "The pressure of the front left tire";
CM_ SG_ 1306 TIRE_RR_statusIsVbattNotOk "Vbatt bit of Rear Right tire status register: TPMS battery is below 2.2V (1) or above (0)";
CM_ SG_ 1306 TIRE_RR_pressure "The pressure of the Rear Right tire";
CM_ SG_ 1816 LAD_D_ParamRq "Diag requested data from host";
CM_ BO_ 1556 "(cycle_time: 1000)";
CM_ SG_ 1556 NLG5_E_T_EXT1 "Ext. temperature sensor 1 defective (if enabled)";
CM_ SG_ 1556 NLG5_W_OD "LED Output driver defective, LEDs cannot be controlled by NLG5 anymore. Charging is still possible.";
CM_ SG_ 1556 NLG5_E_C_TX "CAN transmit buffer >127";
CM_ SG_ 1556 NLG5_E_MOV_I "Mains overvoltage 1 detected";
CM_ SG_ 1556 NLG5_E_P_OM "plausibility battery output voltage measurement wrong";
CM_ SG_ 1556 NLG5_E_SDT_BV "Emergency Shutdown Threshold 'Battery Voltage' is exceeded; see ChargeStar help section 'protective features';  error can only be cleared by cycling power ON-OFF-ON";
CM_ SG_ 1556 NLG5_E_T_DIO "Temperature sensor for diodes defective";
CM_ SG_ 1556 NLG5_E_EP_CRC "Pow EEPROM checksum failure";
CM_ SG_ 1556 NLG5_E_INIT "Initialization error";
CM_ SG_ 1556 NLG5_E_T_EXT2 "Ext. temperature sensor 2 defective (if enabled)";
CM_ SG_ 1556 NLG5_W_SC_M "Save-Charging-Mode reduces primary current to 3.95 A as long as one of the four internal temperature sensors indicates -18deg C or less.";
CM_ SG_ 1556 NLG5_W_PL_BV "Output power limited by low battery voltage";
CM_ SG_ 1556 NLG5_W_PL_IT "Output power limited by charger internal overtemperature";
CM_ SG_ 1556 NLG5_E_C_RX "CAN receiver buffer >127";
CM_ SG_ 1556 NLG5_E_NV_CRC "NVSRAM check sum failure; contains most of the scaling & calibration values, CAN ID's and  charging profile etc.";
CM_ SG_ 1556 NLG5_E_SDT_AH "Emergency Shutdown Threshold 'Amp Hours' is exceeded; see ChargeStar help section 'protective features';  error can only be cleared by cycling power ON-OFF-ON";
CM_ SG_ 1556 NLG5_E_T_EXT3 "Ext. temperature sensor 3 defective (if enabled)";
CM_ SG_ 1556 NLG5_E_WDT "Internal Watchdog Timeout";
CM_ SG_ 1556 NLG5_E_P_MV "plausibility mains voltage measurement wrong";
CM_ SG_ 1556 NLG5_W_C_VOR "Commanded value is out of specified range; max or min applicable value is assumed instead";
CM_ SG_ 1556 NLG5_W_PL_MV "Output power limited by low mains voltage";
CM_ SG_ 1556 NLG5_E_SDT_BT "Emergency Shutdown Threshold 'Battery Temperature' is exceeded; see ChargeStar help section 'protective features';  error can only be cleared by cycling power ON-OFF-ON";
CM_ SG_ 1556 NLG5_E_C_OFF "CAN off, transmit buffer >255";
CM_ SG_ 1556 NLG5_E_C_TO "CAN timeout, no control message received for >300ms";
CM_ SG_ 1556 NLG5_E_OF "output fuse defective";
CM_ SG_ 1556 NLG5_E_T_C "Temperature sensor for prim capacitor defective";
CM_ SG_ 1556 NLG5_E_T_TR "Temperature sensor for transformer defective";
CM_ SG_ 1556 NLG5_W_CM_NA "NLG5 Control message not active";
CM_ SG_ 1556 NLG5_E_B_P "wrong battery polarity;  error can only be cleared by cycling power ON-OFF-ON";
CM_ SG_ 1556 NLG5_E_F_CRC "Flash memory checksum failure";
CM_ SG_ 1556 NLG5_E_MF "Mains fuse defective";
CM_ SG_ 1556 NLG5_E_SC "power stage short circuit condition detected; error can only be cleared by cycling power ON-OFF-ON";
CM_ SG_ 1556 NLG5_E_SDT_CT "Emergency Shutdown Threshold 'Charging Time' is exceeded; see ChargeStar help section 'protective features';  error can only be cleared by cycling power ON-OFF-ON";
CM_ SG_ 1556 NLG5_E_ES_CRC "Sys EEPROM checksum failure";
CM_ SG_ 1556 NLG5_E_MOV_II "Mains overvoltage 2 detected";
CM_ SG_ 1556 NLG5_E_OOV "battery output overvoltage; error can only be cleared by cycling power ON-OFF-ON";
CM_ SG_ 1556 NLG5_E_T_POW "Temperature sensor for prim power stage defective";
CM_ BO_ 1204 "(cycle_time: 100) (send_type: Cyclic)";
CM_ SG_ 1204 LV_CELL_6_isUV "States whether the LV cell #6 is in undervoltage";
CM_ SG_ 1204 LV_CELL_NTC_05_isOT "States whether the LV cell temperature sensor #5 (NTC) detects an over temperature";
CM_ SG_ 1204 LV_CELL_1_isOV "States whether the LV cell #1 is in overvoltage";
CM_ SG_ 1204 LV_CELL_4_isOV "States whether the LV cell #4 is in overvoltage";
CM_ SG_ 1204 LV_CELL_NTC_09_isOT "States whether the LV cell temperature sensor #9 (NTC) detects an over temperature";
CM_ SG_ 1204 LV_CELL_NTC_03_isOT "States whether the LV cell temperature sensor #3 (NTC) detects an over temperature";
CM_ SG_ 1204 LV_CELL_NTC_10_isOT "States whether the LV cell temperature sensor #10 (NTC) detects an over temperature";
CM_ SG_ 1204 LV_CELL_1_isUV "States whether the LV cell #1 is in undervoltage";
CM_ SG_ 1204 LV_CELL_3_isUV "States whether the LV cell #3 is in undervoltage";
CM_ SG_ 1204 LV_CELL_NTC_00_isOT "States whether the LV cell temperature sensor #0 (NTC) detects an over temperature";
CM_ SG_ 1204 LV_CELL_3_isOV "States whether the LV cell #3 is in overvoltage";
CM_ SG_ 1204 LV_CELL_NTC_02_isOT "States whether the LV cell temperature sensor #2 (NTC) detects an over temperature";
CM_ SG_ 1204 LV_CELL_NTC_11_isOT "States whether the LV cell temperature sensor #11 (NTC) detects an over temperature";
CM_ SG_ 1204 LV_CELL_4_isUV "States whether the LV cell #4 is in undervoltage";
CM_ SG_ 1204 LV_CELL_0_isOV "States whether the LV cell #0 is in overvoltage";
CM_ SG_ 1204 LV_CELL_0_isUV "States whether the LV cell #0 is in undervoltage";
CM_ SG_ 1204 LV_CELL_2_isUV "States whether the LV cell #2 is in undervoltage";
CM_ SG_ 1204 LV_CELL_2_isOV "States whether the LV cell #2 is in overvoltage";
CM_ SG_ 1204 LV_CELL_NTC_07_isOT "States whether the LV cell temperature sensor #7 (NTC) detects an over temperature";
CM_ SG_ 1204 LV_CELL_NTC_08_isOT "States whether the LV cell temperature sensor #8 (NTC) detects an over temperature";
CM_ SG_ 1204 LV_CELL_NTC_12_isOT "States whether the LV cell temperature sensor #12 (NTC) detects an over temperature";
CM_ SG_ 1204 LV_CELL_5_isUV "States whether the LV cell #5 is in undervoltage";
CM_ SG_ 1204 LV_CELL_NTC_04_isOT "States whether the LV cell temperature sensor #4 (NTC) detects an over temperature";
CM_ SG_ 1204 LV_CELL_NTC_06_isOT "States whether the LV cell temperature sensor #6 (NTC) detects an over temperature";
CM_ SG_ 1204 LV_CELL_5_isOV "States whether the LV cell #5 is in overvoltage";
CM_ SG_ 1204 LV_CELL_6_isOV "States whether the LV cell #6 is in overvoltage";
CM_ SG_ 1204 LV_CELL_NTC_01_isOT "States whether the LV cell temperature sensor #1 (NTC) detects an over temperature";
CM_ BO_ 1636 "(cycle_time: 2000) (send_type: Cyclic)";
CM_ SG_ 1636 LV_CELL_NTC_10_resistance "The resistance of the NTC #10 in the battery pack expressed in Ohm";
CM_ SG_ 1636 LV_CELL_NTC_11_resistance "The resistance of the NTC #11 in the battery pack expressed in Ohm";
CM_ SG_ 1636 LV_CELL_NTC_06_resistance "The resistance of the NTC #6 in the battery pack expressed in Ohm";
CM_ SG_ 1636 LV_CELL_NTC_07_resistance "The resistance of the NTC #7 in the battery pack expressed in Ohm";
CM_ SG_ 1636 LV_CELL_NTC_08_resistance "The resistance of the NTC #8 in the battery pack expressed in Ohm";
CM_ SG_ 1636 LV_CELL_NTC_09_resistance "The resistance of the NTC #9 in the battery pack expressed in Ohm";
CM_ BO_ 1719 "(cycle_time: 200) (send_type: Cyclic)";
CM_ SG_ 1719 LED_3_red "The red channel of LED #3 of the dashboard";
CM_ SG_ 1719 LED_3_green "The green channel of LED #3 of the dashboard";
CM_ SG_ 1719 LED_3_blue "The blue channel of LED #3 of the dashboard";
CM_ SG_ 1719 LED_4_red "The red channel of LED #4 of the dashboard";
CM_ SG_ 1719 LED_2_red "The red channel of LED #2 of the dashboard";
CM_ SG_ 1719 LED_2_blue "The blue channel of LED #2 of the dashboard";
CM_ SG_ 1719 LED_1_blue "The blue channel of LED #1 of the dashboard";
CM_ SG_ 1719 LED_2_green "The green channel of LED #2 of the dashboard";
CM_ SG_ 1719 LED_4_green "The green channel of LED #4 of the dashboard";
CM_ SG_ 1719 LED_4_blue "The blue channel of LED #4 of the dashboard";
CM_ SG_ 1719 LED_1_red "The red channel of LED #1 of the dashboard";
CM_ SG_ 1719 LED_1_green "The green channel of LED #1 of the dashboard";
CM_ BO_ 1127 "(send_type: CyclicIfActive)";
CM_ SG_ 1127 xcp_payload "xcp payload data";
CM_ BO_ 1602 "(send_type: IfActive)";
CM_ SG_ 1602 FW_majorVersion "firmware major version number";
CM_ SG_ 1602 FW_minorVersion "firmware minor version number";
CM_ SG_ 1602 FW_patchVersion "firmware patch version number";
CM_ BO_ 755 "(cycle_time: 10) (send_type: Cyclic)";
CM_ SG_ 755 SDC_POST_BSPD_isClosed "States whether the SDC post BSPD is closed";
CM_ SG_ 755 SDC_PRE_PUSH_BTNS_isClosed "States whether the SDC per push buttons (hoop right/left) is closed";
CM_ SG_ 755 ASMS_isClosed "States whether the ASMS is closed";
CM_ SG_ 755 SDC_POST_INV_FR_isClosed "States whether the SDC post inverter front right is closed";
CM_ BO_ 710 "(send_type: CyclicIfActive)";
CM_ SG_ 710 xcp_payload "xcp payload data";
CM_ BO_ 1552 "(cycle_time: 100)";
CM_ SG_ 1552 NLG5_S_L_OC_MAX "Output power limited by maximum output current capability of NLG5";
CM_ SG_ 1552 NLG5_S_L_OV "Output power limited by battery output voltage limit";
CM_ SG_ 1552 NLG5_S_EUM "European mains input detected (230V, 50Hz)";
CM_ SG_ 1552 NLG5_S_L_MC "Output power limited by mains current limit";
CM_ SG_ 1552 NLG5_S_L_OC "Output power limited by battery output current limit";
CM_ SG_ 1552 NLG5_S_L_PMAX "Output power limited by maximum power capability of NLG5";
CM_ SG_ 1552 NLG5_S_L_T_CPRIM "Output power limited by temperature of primary capacitors";
CM_ SG_ 1552 NLG5_S_UM_II "US mains level 2 (240VAC / 60Hz) detected";
CM_ SG_ 1552 NLG5_S_BPD_II "Bypass detection bit 2; 00: no bypass, 01: DC bypass detected, 10:AC bypass in phase, 11: AC bypass not in phase";
CM_ SG_ 1552 NLG5_S_ERR "An error has been detected, red LED is ON, no power is output";
CM_ SG_ 1552 NLG5_S_AAC "AUX 12 V Automatic Charging Active";
CM_ SG_ 1552 NLG5_S_WAR "Warning condition on, i.e. charging power limited due to any limiting condition; red LED is blinking";
CM_ SG_ 1552 NLG5_S_L_MO_MAX "Output power limited by maximum output voltage capability of NLG5";
CM_ SG_ 1552 NLG5_S_L_T_BATT "Output power limited by battery temperature";
CM_ SG_ 1552 NLG5_S_BPD_I "Bypass detection bit 1; 00: no bypass, 01: DC bypass detected, 10:AC bypass in phase, 11: AC bypass not in phase";
CM_ SG_ 1552 NLG5_S_L_PI "Output power limited by analog input 'power indicator' (PI) limit";
CM_ SG_ 1552 NLG5_S_UM_I "US mains level 1 (120VAC / 60Hz) detected";
CM_ SG_ 1552 NLG5_S_L_MC_MAX "Output power limited by maximum mains current capability of NLG5";
CM_ SG_ 1552 NLG5_S_L_T_TR "Output power limited by temperature of transformer";
CM_ SG_ 1552 NLG5_S_FAN "Charger cooling fan is active";
CM_ SG_ 1552 NLG5_S_L_CP "Output power limited by control pilot signal (SAE J1772)";
CM_ SG_ 1552 NLG5_S_L_T_DIO "Output power limited by temperature of diodes";
CM_ SG_ 1552 NLG5_S_L_T_POW "Output power limited by temperature of power stage";
CM_ SG_ 1552 NLG5_S_CP_DT "Control pilot signal (SAE J1772) detected ";
CM_ SG_ 1552 NLG5_S_HE "Indicates if hardware enabled, i.e. a hi or lo signal is fed to the 'Power On' pin (pin3 of control connector)";
CM_ BO_ 1554 "(cycle_time: 100)";
CM_ SG_ 1554 NLG5_S_MC_M_PI "Value of mains current limit, commanded by the 'power indicator' (PI) analog input signal";
CM_ SG_ 1554 NLG5_ABV "Aux battery voltage";
CM_ SG_ 1554 NLG5_AHC_EXT "Charge balance obtained via  Ext. Ah counter connected to DI1 / DI2";
CM_ SG_ 1554 NLG5_OC_BO "output current of the booster (if one is present and active)";
CM_ SG_ 1554 NLG5_S_MC_M_CP "Value of mains current limit, commanded by the control pilot (SAE J1772) signal";
CM_ BO_ 1269 "(cycle_time: 500) (send_type: Cyclic)";
CM_ SG_ 1269 TSAC_FAN_pwmDutyCycleStatus "PWM duty cycle percentage for TSAC fans control";
CM_ BO_ 1607 "(send_type: IfActive)";
CM_ SG_ 1607 FW_patchVersion "firmware patch version number";
CM_ SG_ 1607 FW_majorVersion "firmware major version number";
CM_ SG_ 1607 FW_minorVersion "firmware minor version number";
CM_ BO_ 1668 "(cycle_time: 500) (send_type: Cyclic)";
CM_ SG_ 1668 JACKET_RR_NTC_resistance "The resistance of the rear right jacket NTC expressed in Ohm";
CM_ SG_ 1668 RAD_RR_IN_NTC_resistance "The resistance of the rear right IN radiator NTC expressed in Ohm";
CM_ SG_ 1668 RAD_RR_OUT_NTC_resistance "The resistance of the rear right OUT radiator NTC expressed in Ohm";
CM_ BO_ 324 "(cycle_time: 100) (send_type: Cyclic)";
CM_ SG_ 324 LV_BAT_currentSensVoltage "The voltage returned by the current sensor of the LV battery expressed in mV";
CM_ SG_ 324 LV_BAT_summedVoltage "The total voltage of the LV battery pack calculated by summing each cell voltage expressed in mV";
CM_ SG_ 324 LV_BAT_voltage "The total read voltage of the LV battery pack expressed in mV";
CM_ BO_ 1650 "(cycle_time: 500) (send_type: Cyclic)";
CM_ SG_ 1650 COLDPLATE_L_NTC_resistance "The resistance of the left coldplate NTC expressed in Ohm";
CM_ SG_ 1650 JACKET_FL_NTC_resistance "The resistance of the front left jacket NTC expressed in Ohm";
CM_ SG_ 1650 SPARE_NTC_0_resistance "The resistance of the spare NTC #0 expressed in Ohm";
CM_ BO_ 770 "(cycle_time: 10) (send_type: Cyclic)";
CM_ SG_ 770 SDC_POST_CP_PUSH_BTN_isActive "States whether the SDC post cockpit push button is active";
CM_ SG_ 770 SDC_POST_INERTIA_isActive "States whether the SDC post inertia switch is active";
CM_ SG_ 770 SDC_POST_BOTS_isActive "States whether the SDC post BOTS is active";
CM_ BO_ 99 "(cycle_time: 10) (send_type: Cyclic)";
CM_ SG_ 99 BRAKE_PRESS_REAR_voltage "The voltage of the rear brake pressure sensor expressed in mV";
CM_ SG_ 99 COOL_PRESS_LEFT_voltage "The voltage of the left cooling pressure sensor expressed in mV";
CM_ SG_ 99 COOL_PRESS_RIGHT_voltage "The voltage of the right cooling pressure sensor expressed in mV";
CM_ BO_ 1553 "(cycle_time: 100)";
CM_ SG_ 1553 NLG5_OV_ACT "Actual battery output voltage";
CM_ SG_ 1553 NLG5_MC_ACT "Actual mains current";
CM_ SG_ 1553 NLG5_MV_ACT "Actual mains voltage";
CM_ SG_ 1553 NLG5_OC_ACT "output current to the battery";
CM_ BO_ 1175 "(cycle_time: 100) (send_type: Cyclic)";
CM_ SG_ 1175 HVBAT_soc "HV Battery State Of Charge percentage";
CM_ SG_ 1175 ASSI_command "ASSI command state";
CM_ BO_ 1123 "(send_type: CyclicIfActive)";
CM_ SG_ 1123 xcp_payload "xcp payload data";
CM_ BO_ 1129 "(send_type: CyclicIfActive)";
CM_ SG_ 1129 xcp_payload "xcp payload data";
CM_ BO_ 1191 "(cycle_time: 100) (send_type: Cyclic)";
CM_ SG_ 1191 DSPACE_amkInvFR_FSM_State "The state of the AMK Inverter Front Right FSM of dspace";
CM_ SG_ 1191 DSPACE_amkInvRL_FSM_State "The state of the AMK Inverter Rear Left FSM of dspace";
CM_ SG_ 1191 DSPACE_amkInvRR_FSM_State "The state of the AMK Inverter Rear Right FSM of dspace";
CM_ SG_ 1191 DSPACE_main_FSM_State "The state of the main/RTD FSM of dspace";
CM_ SG_ 1191 DSPACE_amkInvFL_FSM_State "The state of the AMK Inverter Front Left FSM of dspace";
CM_ BO_ 1143 "(cycle_time: 70) (send_type: Cyclic)";
CM_ SG_ 1143 autonomousMission_state "Autonomous mission state";
CM_ BO_ 407 "(cycle_time: 10) (send_type: Cyclic)";
CM_ SG_ 407 AS_SDC_closeCMD "Autonomous system SDC closure command";
CM_ SG_ 407 RAD_FAN_pwmDutyCicleCtrl "PWM duty cycle percentage for Radiator Fans control";
CM_ SG_ 407 COOL_PUMPS_speedCtrl "Speed percentage for Cooling Pumps control";
CM_ SG_ 407 BRAKE_LIGHT_activeCMD "The command to turn on the brake light (0 inactive - 1 active)";
CM_ SG_ 407 DASH_SDC_RLY_closeCMD "The command to close the SDC relay (0 open - 1 close)";
CM_ BO_ 1651 "(cycle_time: 500) (send_type: Cyclic)";
CM_ SG_ 1651 SPARE_NTC_1_resistance "The resistance of the spare NTC #1 expressed in Ohm";
CM_ SG_ 1651 COLDPLATE_R_NTC_resistance "The resistance of the right coldplate NTC expressed in Ohm";
CM_ SG_ 1651 JACKET_FR_NTC_resistance "The resistance of the front right jacket NTC expressed in Ohm";
CM_ BO_ 373 "(send_type: IfActive)";
CM_ SG_ 373 No_counter_change_notify "Dashboard response to the counter for EBS test procedure (rolling counter not changing)";
CM_ BO_ 357 "(cycle_time: 200) (send_type: Cyclic)";
CM_ SG_ 357 BTN_RTD_isPressed "Ready To Drive Button pressed";
CM_ SG_ 357 BTN_TS_ON_isPressed "Tractive System ON Button #1 is pressed";
CM_ SG_ 357 BTN_MIS_SEL_isPressed "Mission selection Button pressed";
CM_ BO_ 819 "(cycle_time: 10) (send_type: Cyclic)";
CM_ SG_ 819 LPPS_DAMPER_RL_voltage "The voltage of the linear potentiometer position sensor on the rear left damper expressed in mV";
CM_ SG_ 819 LPPS_DAMPER_RR_voltage "The voltage of the linear potentiometer position sensor on the rear left damper expressed in mV";
CM_ BO_ 65 "(cycle_time: 10) (send_type: Cyclic)";
CM_ SG_ 65 AIR_POS_cmd_isActive "Status of the Positive AIR command";
CM_ SG_ 65 AIR_NEG_isClosed "Status of the Negative AIR mechanical state";
CM_ SG_ 65 AMS_err_isActive "States whether the AMS error is active";
CM_ SG_ 65 IMD_err_isActive "States whether the IMD error is active";
CM_ SG_ 65 AIR_POS_isClosed "Status of the Positive AIR mechanical state";
CM_ SG_ 65 DCBUS_PRECH_RLY_cmd_isActive "Status of the DCBUS Precharge Relay command";
CM_ SG_ 65 TSAL_green_isActive "States whether the TSAL green signal is active";
CM_ SG_ 65 IMP_DCBUS_isActive "States whether the DCBUS Implausibility is active (DCBUS Less then 60V and TS is active)";
CM_ SG_ 65 AIR_NEG_cmd_isActive "Status of the Negative AIR command";
CM_ SG_ 65 DCBUS_PRECH_RLY_isClosed "Status of the DCBUS Precharge Relay mechanical state";
CM_ SG_ 65 DCBUS_isOver60V "States whether the DC BUS volatge is over 60V";
CM_ SG_ 65 IMP_any_isActive "States whether any implausibility is active";
CM_ SG_ 65 IMP_HV_RelaysState_isActive "States whether an implausibility on HV relays (NEG,POS,PRECH) State is active (differene between cmd and mechanical state)";
CM_ SG_ 65 AIR_POS_STG_mechStateSignal_isActive "States whether a Short To Gnd on AIR POS mechanical state signal is active";
CM_ SG_ 65 AIR_NEG_STG_mechStateSignal_isActive "States whether a Short To Gnd on AIR NEG mechanical state signal is active";
CM_ BO_ 1280 "(cycle_time: 100) (send_type: Cyclic)";
CM_ BO_ 1281 "(cycle_time: 100) (send_type: Cyclic)";
CM_ BO_ 1282 "(cycle_time: 100) (send_type: Cyclic)";
CM_ BO_ 678 "(send_type: CyclicIfActive)";
CM_ SG_ 678 xcp_payload "xcp payload data";
CM_ BO_ 23 "(cycle_time: 10) (send_type: Cyclic)";
CM_ SG_ 23 DATETIME_year "Current year expressed as an offset from 1970";
CM_ SG_ 23 DATETIME_month "Current month of the year (1 = January, 12 = December)";
CM_ SG_ 23 DATETIME_day "Current day of the month, from 1 to 31";
CM_ SG_ 23 DATETIME_hours "Current hours of the day (1-24)";
CM_ SG_ 23 DATETIME_minutes "Current minutes of the hour";
CM_ SG_ 23 DATETIME_seconds "Current seconds of the minute";
CM_ SG_ 23 DATETIME_houndresOfASeconds "Current tens of the second";
CM_ BO_ 1601 "(send_type: IfActive)";
CM_ SG_ 1601 FW_majorVersion "firmware major version number";
CM_ SG_ 1601 FW_minorVersion "firmware minor version number";
CM_ SG_ 1601 FW_patchVersion "firmware patch version number";
CM_ BO_ 1290 "(send_type: CyclicIfActive)";
CM_ SG_ 1290 TIRE_FL_statusIsVbattNotOk "Vbatt bit of Front Left tire status register: TPMS battery is below 2.2V (1) or above (0)";
CM_ SG_ 1290 TIRE_FL_temperature "The temperature of the Front Left tire";
CM_ SG_ 1290 TIRE_FR_statusIsVbattNotOk "Vbatt bit of Front Right tire status register: TPMS battery is below 2.2V (1) or above (0)";
CM_ SG_ 1290 TIRE_FR_temperature "The temperature of the Front Right tire";
CM_ SG_ 1290 TIRE_FR_pressure "The pressure of the Front Right tire";
CM_ SG_ 1290 TIRE_FL_sensID "The sensor id of the Front Left tire";
CM_ SG_ 1290 TIRE_FL_statusIsSpinning "Acc bit of Front Left tire status register: wheel is spinning (1) or not (0)";
CM_ SG_ 1290 TIRE_FL_pressure "The pressure of the front left tire";
CM_ SG_ 1290 TIRE_FR_sensID "The sensor id of the front right tire";
CM_ SG_ 1290 TIRE_FR_statusIsSpinning "Acc bit of Front Right tire status register: wheel is spinning (1) or not (0)";
CM_ BO_ 1236 "(cycle_time: 100) (send_type: Cyclic)";
CM_ SG_ 1236 LV_CELL_0_voltage "The voltage of the LV cell #0 expressed in mV";
CM_ SG_ 1236 LV_CELL_1_voltage "The voltage of the LV cell #1 expressed in mV";
CM_ SG_ 1236 LV_CELL_2_voltage "The voltage of the LV cell #2 expressed in mV";
CM_ SG_ 1236 LV_CELL_3_voltage "The voltage of the LV cell #3 expressed in mV";
CM_ BO_ 1604 "(send_type: IfActive)";
CM_ SG_ 1604 FW_majorVersion "firmware major version number";
CM_ SG_ 1604 FW_minorVersion "firmware minor version number";
CM_ SG_ 1604 FW_patchVersion "firmware patch version number";
CM_ BO_ 131 "(cycle_time: 10) (send_type: Cyclic)";
CM_ SG_ 131 COLDPLATE_CIRCUIT_PRESS_voltage "The voltage of the coldplate circuit pressure sensor expressed in mV";
CM_ BO_ 115 "(cycle_time: 10) (send_type: Cyclic)";
CM_ SG_ 115 DISCHARGE_isActive "States whether the discharge is discharging the DCBUS";
CM_ SG_ 115 BSPD_hasError "States whether the BSPD has an error";
CM_ BO_ 1555 "(cycle_time: 1000)";
CM_ SG_ 1555 NLG5_P_TMP "Power stage temperature";
CM_ SG_ 1555 NLG5_TEMP_EXT2 "Value of external battery temperature sensor #2 (if connected and enabled)";
CM_ SG_ 1555 NLG5_TMP_EXT1 "Value of external battery temperature sensor #1 (if connected and enabled)";
CM_ SG_ 1555 NLG5_TMP_EXT3 "Value of external battery temperature sensor #3 (if connected and enabled)";
CM_ BO_ 694 "(send_type: CyclicIfActive)";
CM_ SG_ 694 xcp_payload "xcp payload data";
CM_ BO_ 1122 "(send_type: CyclicIfActive)";
CM_ SG_ 1122 xcp_payload "xcp payload data";
CM_ BO_ 82 "(cycle_time: 10) (send_type: Cyclic)";
CM_ SG_ 82 APPS_0_voltage "The voltage of the APPS #0 expressed in mV";
CM_ SG_ 82 APPS_1_voltage "The voltage of the APPS #1 expressed in mV";
CM_ SG_ 82 STEER_RME_voltage "The voltage of the Steering Wheel RME (rotary magnetic encoder) sensor expressed in mV";
CM_ SG_ 82 BRAKE_PRESS_FRONT_voltage "The voltage of the front brake pressure sensor expressed in mV";
CM_ BO_ 83 "(cycle_time: 10) (send_type: Cyclic)";
CM_ SG_ 83 EMERGENCY_BRAKE_PRESS_PNEU_voltage "The voltage of the emergency brake pressure sensor (pneumatic) expressed in mV";
CM_ SG_ 83 REDUNDANCY_BRAKE_PRESS_PNEU_voltage "The voltage of the redundancy brake pressure sensor (pneumatic) expressed in mV";
CM_ BO_ 1121 "(send_type: CyclicIfActive)";
CM_ SG_ 1121 xcp_payload "xcp payload data";
CM_ BO_ 167 "(cycle_time: 10) (send_type: Cyclic)";
CM_ SG_ 167 ASB_VALVES_CMD "Command of the ASB EBS valves (Stanlio and Ollio)";
CM_ SG_ 167 Rolling_counter "Counter to implement the emergency brake watchdog";
CM_ SG_ 167 TEST_EBS "A boolean for the pre-start EBS valves check";
CM_ BO_ 1620 "(cycle_time: 2000) (send_type: Cyclic)";
CM_ SG_ 1620 LV_CELL_NTC_01_resistance "The resistance of the NTC #1 in the battery pack expressed in Ohm";
CM_ SG_ 1620 LV_CELL_NTC_02_resistance "The resistance of the NTC #2 in the battery pack expressed in Ohm";
CM_ SG_ 1620 LV_CELL_NTC_03_resistance "The resistance of the NTC #3 in the battery pack expressed in Ohm";
CM_ SG_ 1620 LV_CELL_NTC_04_resistance "The resistance of the NTC #4 in the battery pack expressed in Ohm";
CM_ SG_ 1620 LV_CELL_NTC_05_resistance "The resistance of the NTC #5 in the battery pack expressed in Ohm";
CM_ SG_ 1620 LV_CELL_NTC_00_resistance "The resistance of the NTC #0 in the battery pack expressed in Ohm";
CM_ BO_ 1701 "(send_type: IfActive)";
CM_ SG_ 1701 LV_RELAY_overrideState "The override state to force the LV relay: no override (OFF/0), alwasy open (OPEN/1) or always closed (CLOSED/2)";
CM_ SG_ 1701 BMS_LV_diagPWD "The password to enter diagnostic mode of the BMS_LV";
CM_ BO_ 662 "(send_type: CyclicIfActive)";
CM_ SG_ 662 xcp_payload "xcp payload data";
CM_ SG_ 1818 LAD_D_ParamRp "Diag responded data to host";
CM_ BO_ 1667 "(cycle_time: 500) (send_type: Cyclic)";
CM_ SG_ 1667 JACKET_RL_NTC_resistance "The resistance of the rear left jacket NTC expressed in Ohm";
CM_ SG_ 1667 RAD_RL_IN_NTC_resistance "The resistance of the rear left IN radiator NTC expressed in Ohm";
CM_ SG_ 1667 RAD_RL_OUT_NTC_resistance "The resistance of the rear left OUT radiator NTC expressed in Ohm";
CM_ BO_ 726 "(send_type: CyclicIfActive)";
CM_ SG_ 726 xcp_payload "xcp payload data";
CM_ BO_ 1748 "(cycle_time: 2000) (send_type: Cyclic)";
CM_ SG_ 1748 LV_CELL_NTC_12_resistance "The resistance of the NTC #12 in the battery pack expressed in Ohm";
CM_ BO_ 1220 "(cycle_time: 500) (send_type: Cyclic)";
CM_ SG_ 1220 LV_RELAY_isClosed "States whether the LV relay is closed";
CM_ SG_ 1220 LV_RELAY_isRelayOverrideOn "States whether the LV relay override is enabled";
CM_ BO_ 1125 "(send_type: CyclicIfActive)";
CM_ SG_ 1125 xcp_payload "xcp payload data";
CM_ BO_ 1685 "(send_type: IfActive)";
CM_ SG_ 1685 APPS_0_voltageRangeMax "APPS channel #0 maximum range expressed in mV";
CM_ SG_ 1685 APPS_0_voltageRangeMin "APPS channel #0 minimum range expressed in mV";
CM_ SG_ 1685 APPS_1_voltageRangeMax "APPS channel #1 maximum range expressed in mV";
CM_ SG_ 1685 APPS_1_voltageRangeMin "APPS channel #1 minimum range expressed in mV";
CM_ BO_ 1800 "IRTS message placeholder TODO: update this message when you have the specification";
CM_ BO_ 1297 "(cycle_time: 100) (send_type: Cyclic)";
CM_ SG_ 1297 BRAKE_PRESS_FRONT_voltage "Front brake pressure expressed in bar";
CM_ SG_ 1297 EMERGENCY_BRAKE_PRESS_PNEU_voltage "Emergency brake pressure sensor (pneumatic) expressed in bar";
CM_ SG_ 1297 REDUNDANCY_BRAKE_PRESS_PNEU_voltage "Redundancy brake pressure sensor (pneumatic) expressed in bar";
CM_ SG_ 1297 BRAKE_PRESS_REAR_voltage "Rear brake pressure expressed in bar";
CM_ BO_ 646 "(send_type: CyclicIfActive)";
CM_ SG_ 646 xcp_payload "xcp payload data";
CM_ BO_ 802 "(cycle_time: 10) (send_type: Cyclic)";
CM_ SG_ 802 LPPS_DAMPER_FL_voltage "The voltage of the linear potentiometer position sensor on the front left damper expressed in mV";
CM_ SG_ 802 LPPS_DAMPER_FR_voltage "The voltage of the linear potentiometer position sensor on the front right damper expressed in mV";
CM_ BO_ 366 "(cycle_time: 200) (send_type: Cyclic)";
CM_ SG_ 366 BTN_2_isPressed "Steering wheel Button #2 is pressed";
CM_ SG_ 366 BTN_4_isPressed "Steering wheel Button #4 is pressed";
CM_ SG_ 366 BTN_6_isPressed "Steering wheel Button #6 is pressed";
CM_ SG_ 366 BTN_7_isPressed "Steering wheel Button #7 is pressed";
CM_ SG_ 366 ROT_SW_1_state "Rotary Switch 1 state";
CM_ SG_ 366 ROT_SW_3_state "Rotary Switch 3 state";
CM_ SG_ 366 BTN_1_isPressed "Steering wheel Button #1 is pressed";
CM_ SG_ 366 BTN_3_isPressed "Steering wheel Button #3 is pressed";
CM_ SG_ 366 BTN_5_isPressed "Steering wheel Button #5 is pressed";
CM_ SG_ 366 BTN_8_isPressed "Steering wheel Button #8 is pressed";
CM_ SG_ 366 BTN_9_isPressed "Steering wheel Button #9 is pressed";
CM_ SG_ 366 ROT_SW_2_state "Rotary Switch 2 state";
CM_ BO_ 1252 "(cycle_time: 100) (send_type: Cyclic)";
CM_ SG_ 1252 LV_CELL_4_voltage "The voltage of the LV cell #4 expressed in mV";
CM_ SG_ 1252 LV_CELL_5_voltage "The voltage of the LV cell #4 expressed in mV";
CM_ SG_ 1252 LV_CELL_6_voltage "The voltage of the LV cell #4 expressed in mV";
CM_ BO_ 737 "(cycle_time: 10) (send_type: Cyclic)";
CM_ SG_ 737 SDC_post_AMS_IMD_relay_isActive "Shutdown Circuit sensing: post AMS/IMD relay is active status";
CM_ SG_ 737 SDC_TSAC_finalIn_isActive "Shutdown Circuit sensing: TSAC Final Input is active status";
CM_ SG_ 737 SDC_PrechBypassRelay_isClosed "States whether the SDC precharge bypass relay is closed";
CM_ SG_ 737 SDC_TSAC_initialIn_voltage "Shutdown Circuit sensing: TSAC Initial Input voltage";
CM_ SG_ 737 SDC_TSAC_finalIn_voltage "Shutdown Circuit sensing: TSAC Final Input voltage";
CM_ SG_ 737 SDC_TSAC_initialIn_isActive "Shutdown Circuit sensing: TSAC Initial input is active status";
CM_ BO_ 1560 "(cycle_time: 100)";
CM_ SG_ 1560 NLG5_C_CP_V "special signal to tell a charging station equipped with the Control Pilot interface (SAE J1772) to switch on the facility's ventilation (in order to get rid of battery gases like hydrogen, e.g.)";
CM_ SG_ 1560 NLG5_C_C_EL "cycle this value 0-1-0 to clear all latched charger errors ";
CM_ SG_ 1560 NLG5_C_C_EN "Must be ON to enable power stage of the charger";
CM_ SG_ 1560 NLG5_C_MR "Enables CP-State C to request mains voltage";
CM_ SG_ 1560 NLG5_MC_MAX "Maximum current to be drawn from the mains outlet, usually 16A. Must always contain a valid value in order to keep on charging.";
CM_ SG_ 1560 NLG5_OC_COM "Desired battery current. Must always contain a valid value in order to keep on charging.";
CM_ SG_ 1560 NLG5_OV_COM "Desired voltage to be output to the battery. Must always contain a valid value in order to keep on charging.";
CM_ BO_ 1124 "(send_type: CyclicIfActive)";
CM_ SG_ 1124 xcp_payload "xcp payload data";

BA_DEF_ BO_ "GenMsgCycleTime" INT 0 1000;
BA_DEF_ BO_ "GenMsgSendType" ENUM "NoMsgSendType","Cyclic","IfActive","CyclicIfActive","NotUsed";
BA_DEF_ SG_ "GenSigSendType" ENUM "NoSigSendType","Cyclic","OnWrite","OnWriteWithRepetition","OnChange","OnChangeWithRepetition","IfActive","IfActiveWithRepetition","NotUsed";
BA_DEF_DEF_ "GenMsgCycleTime" 0;
BA_DEF_DEF_ "GenMsgSendType" "NoMsgSendType";
BA_DEF_DEF_ "GenSigSendType" "NoSigSendType";
BA_ "GenMsgSendType" BO_ 646 3;
BA_ "GenMsgSendType" BO_ 439 1;
BA_ "GenMsgSendType" BO_ 115 1;
BA_ "GenMsgSendType" BO_ 83 1;
BA_ "GenMsgSendType" BO_ 662 3;
BA_ "GenMsgSendType" BO_ 1748 1;
BA_ "GenMsgSendType" BO_ 1125 3;
BA_ "GenMsgSendType" BO_ 357 1;
BA_ "GenMsgSendType" BO_ 1269 1;
BA_ "GenMsgSendType" BO_ 1123 3;
BA_ "GenMsgSendType" BO_ 1281 1;
BA_ "GenMsgSendType" BO_ 1122 3;
BA_ "GenMsgSendType" BO_ 82 1;
BA_ "GenMsgSendType" BO_ 1605 2;
BA_ "GenMsgSendType" BO_ 1306 3;
BA_ "GenMsgSendType" BO_ 1191 1;
BA_ "GenMsgSendType" BO_ 1143 1;
BA_ "GenMsgSendType" BO_ 1667 1;
BA_ "GenMsgSendType" BO_ 737 1;
BA_ "GenMsgSendType" BO_ 1204 1;
BA_ "GenMsgSendType" BO_ 710 3;
BA_ "GenMsgSendType" BO_ 726 3;
BA_ "GenMsgSendType" BO_ 1127 3;
BA_ "GenMsgSendType" BO_ 1651 1;
BA_ "GenMsgSendType" BO_ 1604 2;
BA_ "GenMsgSendType" BO_ 1701 2;
BA_ "GenMsgSendType" BO_ 1175 1;
BA_ "GenMsgSendType" BO_ 99 1;
BA_ "GenMsgSendType" BO_ 819 1;
BA_ "GenMsgSendType" BO_ 1236 1;
BA_ "GenMsgSendType" BO_ 366 1;
BA_ "GenMsgSendType" BO_ 455 1;
BA_ "GenMsgSendType" BO_ 1719 1;
BA_ "GenMsgSendType" BO_ 1668 1;
BA_ "GenMsgSendType" BO_ 407 1;
BA_ "GenMsgSendType" BO_ 167 1;
BA_ "GenMsgSendType" BO_ 802 1;
BA_ "GenMsgSendType" BO_ 1290 3;
BA_ "GenMsgSendType" BO_ 1252 1;
BA_ "GenMsgSendType" BO_ 755 1;
BA_ "GenMsgSendType" BO_ 1607 2;
BA_ "GenMsgSendType" BO_ 65 1;
BA_ "GenMsgSendType" BO_ 1124 3;
BA_ "GenMsgSendType" BO_ 1602 2;
BA_ "GenMsgSendType" BO_ 1129 3;
BA_ "GenMsgSendType" BO_ 1280 1;
BA_ "GenMsgSendType" BO_ 694 3;
BA_ "GenMsgSendType" BO_ 131 1;
BA_ "GenMsgSendType" BO_ 1685 2;
BA_ "GenMsgSendType" BO_ 1636 1;
BA_ "GenMsgSendType" BO_ 324 1;
BA_ "GenMsgSendType" BO_ 678 3;
BA_ "GenMsgSendType" BO_ 1282 1;
BA_ "GenMsgSendType" BO_ 1620 1;
BA_ "GenMsgSendType" BO_ 1121 3;
BA_ "GenMsgSendType" BO_ 1220 1;
BA_ "GenMsgSendType" BO_ 1297 1;
BA_ "GenMsgSendType" BO_ 1601 2;
BA_ "GenMsgSendType" BO_ 373 2;
BA_ "GenMsgSendType" BO_ 23 1;
BA_ "GenMsgSendType" BO_ 1603 2;
BA_ "GenMsgSendType" BO_ 1650 1;
BA_ "GenMsgSendType" BO_ 770 1;
BA_ "GenMsgCycleTime" BO_ 357 200;
BA_ "GenMsgCycleTime" BO_ 819 10;
BA_ "GenMsgCycleTime" BO_ 1282 100;
BA_ "GenMsgCycleTime" BO_ 1220 500;
BA_ "GenMsgCycleTime" BO_ 1560 100;
BA_ "GenMsgCycleTime" BO_ 439 100;
BA_ "GenMsgCycleTime" BO_ 455 100;
BA_ "GenMsgCycleTime" BO_ 755 10;
BA_ "GenMsgCycleTime" BO_ 82 10;
BA_ "GenMsgCycleTime" BO_ 324 100;
BA_ "GenMsgCycleTime" BO_ 1668 500;
BA_ "GenMsgCycleTime" BO_ 770 10;
BA_ "GenMsgCycleTime" BO_ 1667 500;
BA_ "GenMsgCycleTime" BO_ 802 10;
BA_ "GenMsgCycleTime" BO_ 737 10;
BA_ "GenMsgCycleTime" BO_ 1636 2000;
BA_ "GenMsgCycleTime" BO_ 1719 200;
BA_ "GenMsgCycleTime" BO_ 1620 2000;
BA_ "GenMsgCycleTime" BO_ 1748 2000;
BA_ "GenMsgCycleTime" BO_ 1252 100;
BA_ "GenMsgCycleTime" BO_ 1554 100;
BA_ "GenMsgCycleTime" BO_ 1552 100;
BA_ "GenMsgCycleTime" BO_ 23 10;
BA_ "GenMsgCycleTime" BO_ 1280 100;
BA_ "GenMsgCycleTime" BO_ 115 10;
BA_ "GenMsgCycleTime" BO_ 1555 1000;
BA_ "GenMsgCycleTime" BO_ 366 200;
BA_ "GenMsgCycleTime" BO_ 1556 1000;
BA_ "GenMsgCycleTime" BO_ 99 10;
BA_ "GenMsgCycleTime" BO_ 1553 100;
BA_ "GenMsgCycleTime" BO_ 407 10;
BA_ "GenMsgCycleTime" BO_ 1204 100;
BA_ "GenMsgCycleTime" BO_ 1650 500;
BA_ "GenMsgCycleTime" BO_ 1281 100;
BA_ "GenMsgCycleTime" BO_ 83 10;
BA_ "GenMsgCycleTime" BO_ 1143 70;
BA_ "GenMsgCycleTime" BO_ 1651 500;
BA_ "GenMsgCycleTime" BO_ 1236 100;
BA_ "GenMsgCycleTime" BO_ 167 10;
BA_ "GenMsgCycleTime" BO_ 1297 100;
BA_ "GenMsgCycleTime" BO_ 1269 500;
BA_ "GenMsgCycleTime" BO_ 65 10;
BA_ "GenMsgCycleTime" BO_ 131 10;
BA_ "GenMsgCycleTime" BO_ 1175 100;
BA_ "GenMsgCycleTime" BO_ 1191 100;

VAL_ 1191 DSPACE_main_FSM_State 1 "PRECHARGE" 2 "TS ON" 3 "RTD REQUEST" 4 "RTD" 5 "TS OFF" 255 "DISCHARGE" 0 "IDLE";
VAL_ 1191 DSPACE_amkInvFL_FSM_State 1 "LV ON " 2 "TS ON" 3 "RTD" 4 "MOTOR DRIVE" 5 "INTERM ERROR" 6 "HARD ERROR" 0 "RESET";
VAL_ 1191 DSPACE_amkInvFR_FSM_State 5 "INTERM ERROR" 6 "HARD ERROR" 0 "RESET" 1 "LV ON " 2 "TS ON" 3 "RTD" 4 "MOTOR DRIVE";
VAL_ 1191 DSPACE_amkInvRL_FSM_State 1 "LV ON " 2 "TS ON" 3 "RTD" 4 "MOTOR DRIVE" 5 "INTERM ERROR" 6 "HARD ERROR" 0 "RESET";
VAL_ 1191 DSPACE_amkInvRR_FSM_State 5 "INTERM ERROR" 6 "HARD ERROR" 0 "RESET" 1 "LV ON " 2 "TS ON" 3 "RTD" 4 "MOTOR DRIVE";
VAL_ 1282 ASSI_Status 1 "AS_status_off" 2 "AS_status_ready" 3 "AS_status_driving" 4 "AS_status_emergency" 5 "AS_status_finished";
VAL_ 1282 ASB_EBS_state 3 "ASB_EBS_state_activated" 1 "ASB_EBS_state_deactivated" 2 "ASB_EBS_state_initial_checkup_passed";
VAL_ 1282 AMI_state 5 "AMI_state_inspection" 6 "AMI_state_autocross" 1 "AMI_state_acceleration" 2 "AMI_state_skidpad" 3 "AMI_state_trackdrive" 4 "AMI_state_braketest";
VAL_ 1282 ASB_redundancy_state 1 "ASB_redundancy_state_deactivated" 2 "ASB_redundancy_state_engaged" 3 "ASB_redundancy_state_initial_checkup_passed";
VAL_ 167 ASB_VALVES_CMD 2 "Stanlio_brakes" 3 "Both_brake" 4 "No_brakes" 1 "Ollio_brakes";
VAL_ 1701 LV_RELAY_overrideState 0 "LV_RLY_OVERRIDE_OFF" 1 "LV_RLY_OVERRIDE_OPEN" 2 "LV_RLY_OVERRIDE_CLOSED";
